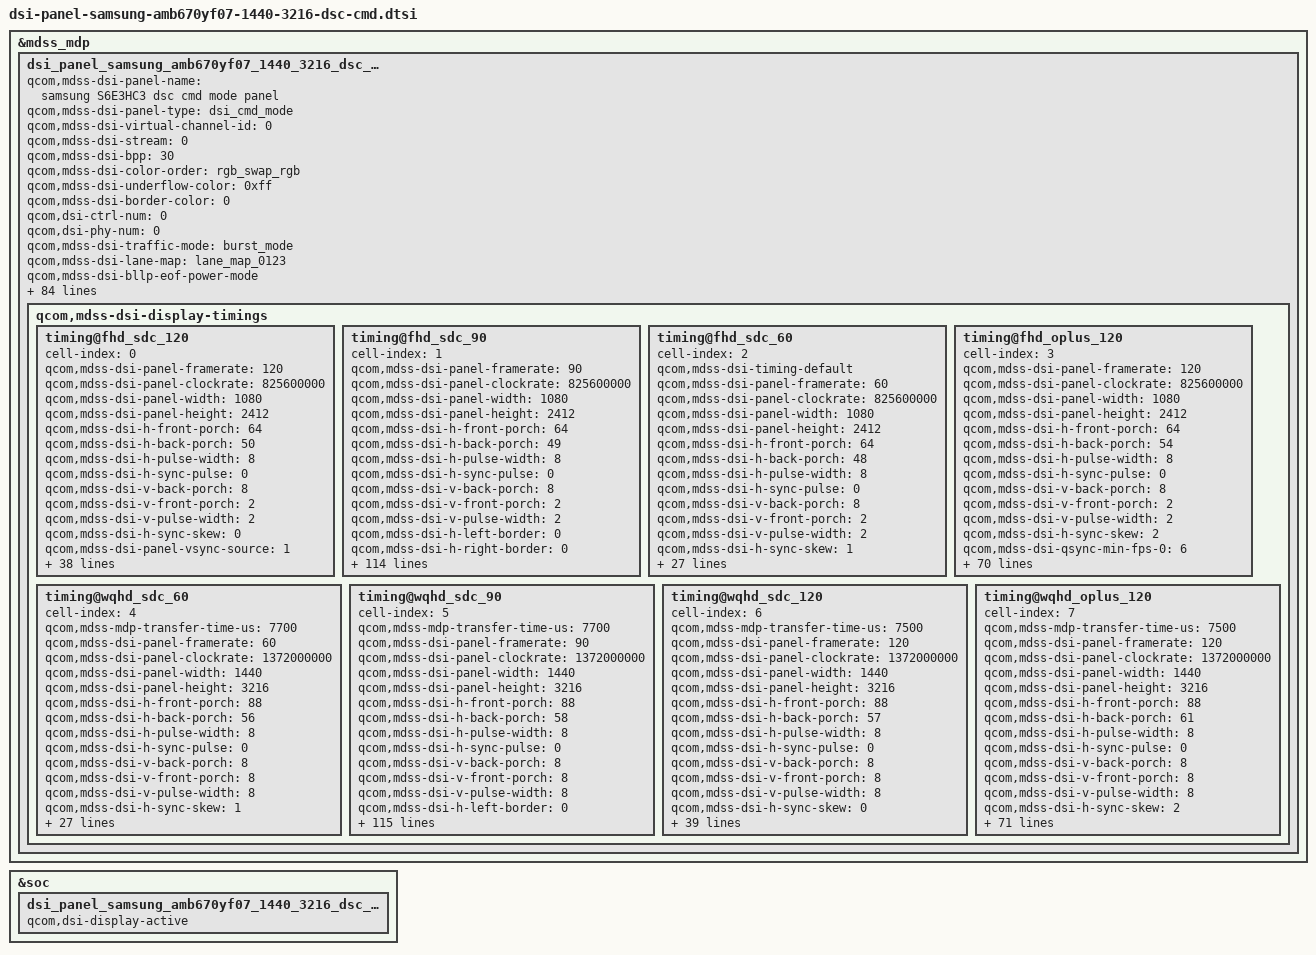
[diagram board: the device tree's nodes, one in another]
&mdss_mdp {
	dsi_panel_samsung_amb670yf07_1440_3216_dsc_cmd: qcom,mdss_dsi_panel_samsung_amb670yf07_1440_3216_dsc_cmd {
		qcom,mdss-dsi-panel-name = "samsung S6E3HC3 dsc cmd mode panel";
		qcom,mdss-dsi-panel-type = "dsi_cmd_mode";
		qcom,mdss-dsi-virtual-channel-id = <0>;
		qcom,mdss-dsi-stream = <0>;
		qcom,mdss-dsi-bpp = <30>;
		qcom,mdss-dsi-color-order = "rgb_swap_rgb";
		qcom,mdss-dsi-underflow-color = <0xff>;
		qcom,mdss-dsi-border-color = <0>;
		qcom,dsi-ctrl-num = <0>;
		qcom,dsi-phy-num = <0>;
		qcom,mdss-dsi-traffic-mode = "burst_mode";
		qcom,mdss-dsi-lane-map = "lane_map_0123";
		qcom,mdss-dsi-bllp-eof-power-mode;
		qcom,mdss-dsi-bllp-power-mode;
		qcom,mdss-dsi-lane-0-state;
		qcom,mdss-dsi-lane-1-state;
		qcom,mdss-dsi-lane-2-state;
		qcom,mdss-dsi-lane-3-state;
		qcom,mdss-dsi-dma-trigger = "trigger_sw";
		qcom,mdss-dsi-mdp-trigger = "none";
		qcom,mdss-dsi-reset-sequence = <1 10>, <0 5>, <1 10>;
		qcom,mdss-pan-physical-width-dimension = <70>;
		qcom,mdss-pan-physical-height-dimension = <156>;
		qcom,mdss-dsi-te-check-enable;
		qcom,mdss-dsi-te-using-te-pin;
		qcom,mdss-dsi-te-pin-select = <1>;
		qcom,mdss-dsi-te-dcs-command = <1>;
		qcom,mdss-dsi-wr-mem-start = <0x2c>;
		qcom,mdss-dsi-wr-mem-continue = <0x3c>;
		//qcom,mdss-dsi-lp11-init;
		qcom,mdss-dsi-init-delay-us = <1000>;
		qcom,mdss-dsi-panel-jitter = <0x4 0x1>;
		qcom,dynamic-mode-switch-enabled;
		qcom,dynamic-mode-switch-type = "dynamic-resolution-switch-immediate";
		/* HDR Setting */
		qcom,mdss-dsi-panel-hdr-enabled;
		qcom,mdss-dsi-panel-hdr-color-primaries = <15635 16450 34000 16000 13250 34500 7500 3000>;
		qcom,mdss-dsi-panel-peak-brightness = <5400000>;
		qcom,mdss-dsi-panel-average-brightness = <2000000>;
		qcom,mdss-dsi-panel-blackness-level = <2000>;

		qcom,esd-check-enabled;
		qcom,mdss-dsi-panel-status-check-mode = "reg_read";
		qcom,mdss-dsi-panel-status-command = [06 01 00 01 00 00 01 0A];
		qcom,mdss-dsi-panel-status-command-state = "dsi_lp_mode";
		qcom,mdss-dsi-panel-status-value = <
			0x9D
			0x9F
		>;
		qcom,mdss-dsi-panel-status-read-length = <1>;
		oplus,mdss-dsi-panel-status-match-modes = <0x00000000>;
		//oplus,esd-debug-enabled;

		qcom,mdss-dsi-display-timings {
			timing@fhd_sdc_120 {
				#include "dsi-panel-samsung-amb670yf07-1440-3216-dsc-cmd-common.dtsi"
				//qcom,mdss-mdp-transfer-time-us = <6000>;
				cell-index = <0>;
				qcom,mdss-dsi-panel-framerate = <120>;
				qcom,mdss-dsi-panel-clockrate = <825600000>;
				qcom,mdss-dsi-panel-width = <1080>;
				qcom,mdss-dsi-panel-height = <2412>;
				qcom,mdss-dsi-h-front-porch = <64>;
				qcom,mdss-dsi-h-back-porch = <50>;
				qcom,mdss-dsi-h-pulse-width = <8>;
				qcom,mdss-dsi-h-sync-pulse = <0>;
				qcom,mdss-dsi-v-back-porch = <8>;
				qcom,mdss-dsi-v-front-porch = <2>;
				qcom,mdss-dsi-v-pulse-width = <2>;

				/* SDC ADFR */
				qcom,mdss-dsi-h-sync-skew = <0>;
				qcom,mdss-dsi-panel-vsync-source = <1>;
				oplus,adfr-fakeframe-config = <3>;
				oplus,adfr-fakeframe-deferred-time = <6>;		/* period*0.7 */
				qcom,mdss-dsi-qsync-min-fps-0 = <1314>;
				qcom,mdss-dsi-qsync-min-fps-1 = <1314>;
				qcom,mdss-dsi-fakeframe-command = [
					05 00 00 40 00 00 01 2C
					05 00 00 40 00 00 01 3C
					05 00 00 40 00 00 01 2C
					05 00 00 40 00 00 01 3C
					05 00 00 00 00 00 01 00
				];

				qcom,mdss-dsi-timing-switch-command = [
					/* CASET/PASET Setting */
					39 00 00 40 00 00 05 2A 00 00 04 37
					39 00 00 40 00 00 05 2B 00 00 09 6B
					/* Scaler Setting */
					39 00 00 40 00 00 03 F0 5A 5A
					15 00 00 40 00 00 02 C3 89
					39 00 00 40 00 00 04 B0 00 24 C3
					39 00 00 40 00 00 12 C3 FD 00 FD 00 FD 00 FD 00 FD 00 FD 00 FD 00 FD 00 FD
					39 00 00 40 00 00 04 B0 00 3A C3
					39 00 00 40 00 00 12 C3 B0 00 B0 00 B0 00 B0 00 B0 00 B0 00 B0 00 B0 00 B0
					39 00 00 40 00 00 04 B0 00 50 C3
					39 00 00 40 00 00 12 C3 43 00 43 00 43 00 43 00 43 00 43 00 43 00 43 00 43
					39 00 00 40 00 00 04 B0 00 61 C3
					39 00 00 40 00 00 17 C3 CC CC CC CC C0 FE 00 FE 00 FE 00 FE 00 FE 00 FE 00 FE 00 FE 00 FE
					39 00 00 40 00 00 03 F0 A5 A5
					/* OPLUS ADFR OFF */
					39 00 00 40 00 00 03 F0 5A 5A
					39 00 00 40 00 00 03 FC 5A 5A
					15 00 00 40 00 00 02 B9 00						/* TP shift fixed */
					39 00 00 40 00 00 04 B0 00 02 60
					15 00 00 40 00 00 02 60 00						/* OPLUS ADFR OFF */
					39 00 00 40 00 00 03 F2 00 01					/* 0x01,0x00:ADFR ON setting 0x00,0x01:ADFR OFF Setting */
					15 00 00 40 00 00 02 F7 0F
					39 00 00 40 00 00 03 FC A5 A5
					39 00 00 40 00 00 03 F0 A5 A5

					/* TSP_SYNC1 Fixed Setting */
					39 00 00 40 00 00 03 F0 5A 5A
					39 00 00 40 00 00 04 B0 00 22 B9
					39 00 00 40 00 00 03 B9 A1 B1
					39 00 00 40 00 00 04 B0 00 3A B9
					15 00 00 40 00 00 02 B9 02						/* TSP_VSYNC Fixed TE 02:120 03:90 05:60 */
					39 00 00 40 00 00 04 B0 00 26 B9
					39 00 00 40 00 00 03 B9 00 00
					15 00 00 40 00 00 02 F7 0F
					39 00 00 40 00 00 03 F0 A5 A5
					/* TSP_SYNC3 Fixed Setting */
					39 00 00 40 00 00 03 F0 5A 5A
					39 00 00 40 00 00 04 B0 00 24 B9
					15 00 00 40 00 00 02 B9 21
					39 00 00 40 00 00 04 B0 00 38 B9
					15 00 00 40 00 00 02 B9 02						/* TSP_VSYNC Fixed TE 02:120 03:90 05:60 */
					39 00 00 40 00 00 04 B0 00 2A B9
					39 00 00 40 00 00 03 B9 00 00
					15 00 00 40 00 00 02 F7 0F
					39 00 00 40 00 00 03 F0 A5 A5

					/* 120hz Transition */
					39 00 00 40 00 00 03 F0 5A 5A
					39 00 00 40 00 00 04 B0 00 16 F2
					39 00 00 40 00 00 03 F2 1B 50
					39 00 00 40 00 00 04 B0 00 08 CB				/* power saving */
					15 00 00 40 00 00 02 CB 24
					15 00 00 40 00 00 02 60 00
					39 00 00 40 00 00 03 BD 23 02
					39 00 00 40 00 00 04 B0 00 10 BD
					15 00 00 40 00 00 02 BD 00
					39 00 00 40 00 00 04 B0 00 16 BD
					15 00 00 40 00 00 02 BD 77
					39 00 00 40 00 00 04 B0 00 14 BD
					15 00 00 40 00 00 02 BD 00
					15 00 00 40 00 00 02 F7 0F
					39 00 00 00 00 00 03 F0 A5 A5
				];
				qcom,mdss-dsi-on-command = [
					/* DSC Setting */
					39 00 00 00 00 00 5A 9E 12
					00 00 AB 30 80 09 6C 04 38
					00 24 02 1C 02 1C 02 00 02
					3B 00 20 03 35 00 07 00 0E
					03 34 02 D4 18 00 10 F0 07
					10 20 00 06 0F 0F 33 0E 1C
					2A 38 46 54 62 69 70 77 79
					7B 7D 7E 02 02 22 00 2A 40
					2A BE 3A FC 3A FA 3A F8 3B
					38 3B 78 3B B6 4B B6 4B F4
					4B F4 6C 34 84 74 00
					15 00 00 00 00 00 02 9D 01

					/* Sleep Out(11h) */
					05 00 00 00 06 00 01 11

					/* TSP_SYNC1 Fixed Setting */
					39 00 00 40 00 00 03 F0 5A 5A
					39 00 00 40 00 00 04 B0 00 22 B9
					39 00 00 40 00 00 03 B9 A1 B1
					39 00 00 40 00 00 04 B0 00 3A B9
					15 00 00 40 00 00 02 B9 02						/* TSP_VSYNC Fixed TE 02:120 03:90 05:60 */
					39 00 00 40 00 00 04 B0 00 26 B9
					39 00 00 40 00 00 03 B9 00 00
					15 00 00 40 00 00 02 F7 0F
					39 00 00 00 00 00 03 F0 A5 A5
					/* TSP_SYNC3 Fixed Setting */
					39 00 00 40 00 00 03 F0 5A 5A
					39 00 00 40 00 00 04 B0 00 24 B9
					15 00 00 40 00 00 02 B9 21
					39 00 00 40 00 00 04 B0 00 38 B9
					15 00 00 40 00 00 02 B9 02						/* TSP_VSYNC Fixed TE 02:120 03:90 05:60 */
					39 00 00 40 00 00 04 B0 00 2A B9
					39 00 00 40 00 00 03 B9 00 00
					15 00 00 40 00 00 02 F7 0F
					39 00 00 00 79 00 03 F0 A5 A5

					/* 120hz Transition */
					39 00 00 40 00 00 03 F0 5A 5A
					39 00 00 40 00 00 04 B0 00 16 F2
					39 00 00 40 00 00 03 F2 1B 50
					39 00 00 40 00 00 04 B0 00 08 CB				/* power saving */
					15 00 00 40 00 00 02 CB 24
					15 00 00 40 00 00 02 60 00
					39 00 00 40 00 00 03 BD 23 02
					39 00 00 40 00 00 04 B0 00 10 BD
					15 00 00 40 00 00 02 BD 00
					39 00 00 40 00 00 04 B0 00 16 BD
					15 00 00 40 00 00 02 BD 77
					39 00 00 40 00 00 04 B0 00 14 BD
					15 00 00 40 00 00 02 BD 00
					15 00 00 40 00 00 02 F7 0F
					39 00 00 00 00 00 03 F0 A5 A5

					/* Common Setting */
					39 00 00 40 00 00 03 F0 5A 5A
					39 00 00 40 00 00 03 F2 00 01					/* FQ_CON Setting */
					39 00 00 00 00 00 03 F0 A5 A5
					/* TE(Vsync) ON */
					39 00 00 40 00 00 03 F0 5A 5A
					15 00 00 40 00 00 02 35 00
					15 00 00 40 00 00 02 B9 00
					39 00 00 00 00 00 03 F0 A5 A5
					/* CASET/PASET Setting */
					39 00 00 00 00 00 05 2A 00 00 04 37
					39 00 00 00 00 00 05 2B 00 00 09 6B
					/* Scaler Setting */
					39 00 00 40 00 00 03 F0 5A 5A
					15 00 00 40 00 00 02 C3 89
					39 00 00 40 00 00 04 B0 00 24 C3
					39 00 00 40 00 00 12 C3 FD 00 FD 00 FD 00 FD 00 FD 00 FD 00 FD 00 FD 00 FD
					39 00 00 40 00 00 04 B0 00 3A C3
					39 00 00 40 00 00 12 C3 B0 00 B0 00 B0 00 B0 00 B0 00 B0 00 B0 00 B0 00 B0
					39 00 00 40 00 00 04 B0 00 50 C3
					39 00 00 40 00 00 12 C3 43 00 43 00 43 00 43 00 43 00 43 00 43 00 43 00 43
					39 00 00 40 00 00 04 B0 00 61 C3
					39 00 00 40 00 00 17 C3 CC CC CC CC C0 FE 00 FE 00 FE 00 FE 00 FE 00 FE 00 FE 00 FE 00 FE
					39 00 00 00 00 00 03 F0 A5 A5
					/* Pre-charge time setting */
					39 00 00 40 00 00 03 F0 5A 5A
					39 00 00 40 00 00 04 B0 00 2B F6
					39 00 00 40 00 00 04 F6 60 63 69
					15 00 00 40 00 00 02 F7 0F
					39 00 00 00 00 00 03 F0 A5 A5
					/* HLPM Power Saving */
					39 00 00 40 00 00 03 F0 5A 5A
					39 00 00 40 00 00 04 B0 00 46 F4
					15 00 00 40 00 00 02 F4 08
					39 00 00 00 00 00 03 F0 A5 A5
					/* DCDC setting of AOD Sequence */
					39 00 00 40 00 00 03 F0 5A 5A
					39 00 00 40 00 00 04 B0 00 18 B1
					39 00 00 40 00 00 02 B1 05
					39 00 00 00 00 00 03 F0 A5 A5

					/* Brightness Control */
					39 00 00 40 00 00 03 F0 5A 5A
					39 00 00 40 00 00 04 B0 00 0D 63
					15 00 00 40 00 00 02 63 01						/* Dimming Setting */
					39 00 00 40 00 00 04 B0 00 0C 63
					15 00 00 40 00 00 02 63 20
					39 00 00 00 00 00 03 F0 A5 A5
					15 00 00 00 00 00 02 53 28
					15 00 00 00 00 00 02 F7 0F
					/* ACL Mode */
					39 00 00 40 00 00 03 F0 5A 5A
					15 00 00 40 00 00 02 55 00
					39 00 00 00 00 00 03 F0 A5 A5
					/* OPEC Setting */
					39 00 00 40 00 00 03 F0 5A 5A
					39 00 00 40 00 00 04 B0 00 52 1F
					15 00 00 40 00 00 02 1F 02
					39 00 00 40 00 00 04 B0 00 54 1F
					15 00 00 40 00 00 02 1F 00
					39 00 00 00 00 00 03 F0 A5 A5
				];

				qcom,mdss-dsi-qsync-on-commands = [
					/* SDC Auto On */
					39 00 00 40 00 00 03 F0 5A 5A
					15 00 00 40 00 00 02 BD 23
					39 00 00 40 00 00 04 B0 00 10 BD
					15 00 00 40 00 00 02 BD 10
					39 00 00 40 00 00 04 B0 00 16 BD
					15 00 00 40 00 00 02 BD 03
					15 00 00 40 00 00 02 F7 0F
					39 00 00 00 00 00 03 F0 A5 A5
				];
				qcom,mdss-dsi-qsync-off-commands = [
					/* SDC Auto Off */
					39 00 00 40 00 00 03 F0 5A 5A
					15 00 00 40 00 00 02 BD 23
					39 00 00 40 00 00 04 B0 00 10 BD
					15 00 00 40 00 00 02 BD 00
					39 00 00 40 00 00 04 B0 00 16 BD
					15 00 00 40 00 00 02 BD 77
					15 00 00 40 00 00 02 F7 0F
					39 00 00 00 00 00 03 F0 A5 A5
				];
				qcom,mdss-dsi-qsync-min-fps-0-command = [
					/* SDC Auto Off */
					39 00 00 40 00 00 03 F0 5A 5A
					39 00 00 40 00 00 04 B0 00 14 BD
					15 00 00 40 00 00 02 BD 00
					15 00 00 40 00 00 02 F7 0F
					39 00 00 00 00 00 03 F0 A5 A5
				];
				qcom,mdss-dsi-qsync-min-fps-1-command = [
					/* SDC Auto On */
					39 00 00 40 00 00 03 F0 5A 5A
					39 00 00 40 00 00 04 B0 00 14 BD
					15 00 00 40 00 00 02 BD 00
					15 00 00 40 00 00 02 F7 0F
					39 00 00 00 00 00 03 F0 A5 A5
				];

				qcom,mdss-dsi-fakeframe-command-state = "dsi_hs_mode";
				qcom,mdss-dsi-qsync-on-commands-state ="dsi_hs_mode";
				qcom,mdss-dsi-qsync-off-commands-state ="dsi_hs_mode";
				qcom,mdss-dsi-qsync-min-fps-0-command-state = "dsi_hs_mode";
				qcom,mdss-dsi-qsync-min-fps-1-command-state = "dsi_hs_mode";
				qcom,panel-roi-alignment=<1080 36 1080 36 1080 36>;
				qcom,partial-update-enabled = "single_roi";

				qcom,lm-split = <540 540>;
				qcom,mdss-dsc-slice-height = <36>;
				qcom,mdss-dsc-slice-width = <540>;
			};

			timing@fhd_sdc_90 {
				//qcom,mdss-mdp-transfer-time-us = <6000>;
				cell-index = <1>;
				qcom,mdss-dsi-panel-framerate = <90>;
				qcom,mdss-dsi-panel-clockrate = <825600000>;
				qcom,mdss-dsi-panel-width = <1080>;
				qcom,mdss-dsi-panel-height = <2412>;
				qcom,mdss-dsi-h-front-porch = <64>;
				qcom,mdss-dsi-h-back-porch = <49>;
				qcom,mdss-dsi-h-pulse-width = <8>;
				qcom,mdss-dsi-h-sync-pulse = <0>;
				qcom,mdss-dsi-v-back-porch = <8>;
				qcom,mdss-dsi-v-front-porch = <2>;
				qcom,mdss-dsi-v-pulse-width = <2>;
				qcom,mdss-dsi-h-left-border = <0>;
				qcom,mdss-dsi-h-right-border = <0>;
				qcom,mdss-dsi-v-top-border = <0>;
				qcom,mdss-dsi-v-bottom-border = <0>;
				qcom,mdss-dsi-panel-jitter = <0x4 0x1>;

				/* ofp config */
				oplus,ofp-need-to-separate-backlight;
				oplus,ofp-hbm-on-period = <2>;

				/* SDC ADFR */
				qcom,mdss-dsi-h-sync-skew = <0>;
				qcom,mdss-dsi-panel-vsync-source = <1>;
				oplus,adfr-fakeframe-config = <3>;
				oplus,adfr-fakeframe-deferred-time = <8>;		/* period*0.7 */
				qcom,mdss-dsi-qsync-min-fps-0 = <1314>;
				qcom,mdss-dsi-qsync-min-fps-1 = <1314>;
				qcom,mdss-dsi-fakeframe-command = [
					05 00 00 40 00 00 01 2C
					05 00 00 40 00 00 01 3C
					05 00 00 40 00 00 01 2C
					05 00 00 40 00 00 01 3C
					05 00 00 00 00 00 01 00
				];
				qcom,mdss-dsi-adfr-pre-switch-command = [
					39 00 00 40 00 00 03 F0 5A 5A					/* Level2 key Access Enable */
					39 00 00 40 00 00 04 B0 00 14 BD
					15 00 00 40 00 00 02 BD 00						/* SDC auto mode min == max */
					15 00 00 40 00 00 02 BD 23						/* 21 : Manual On  23 Auto On */
					15 00 00 40 00 00 02 F7 0F
					39 00 00 00 00 00 03 F0 A5 A5					/* Level2 key Access Disable */
				];

				qcom,mdss-dsi-timing-switch-command = [
					/* CASET/PASET Setting */
					39 00 00 40 00 00 05 2A 00 00 04 37
					39 00 00 40 00 00 05 2B 00 00 09 6B
					/* Scaler Setting */
					39 00 00 40 00 00 03 F0 5A 5A
					15 00 00 40 00 00 02 C3 89
					39 00 00 40 00 00 04 B0 00 24 C3
					39 00 00 40 00 00 12 C3 FD 00 FD 00 FD 00 FD 00 FD 00 FD 00 FD 00 FD 00 FD
					39 00 00 40 00 00 04 B0 00 3A C3
					39 00 00 40 00 00 12 C3 B0 00 B0 00 B0 00 B0 00 B0 00 B0 00 B0 00 B0 00 B0
					39 00 00 40 00 00 04 B0 00 50 C3
					39 00 00 40 00 00 12 C3 43 00 43 00 43 00 43 00 43 00 43 00 43 00 43 00 43
					39 00 00 40 00 00 04 B0 00 61 C3
					39 00 00 40 00 00 17 C3 CC CC CC CC C0 FE 00 FE 00 FE 00 FE 00 FE 00 FE 00 FE 00 FE 00 FE
					39 00 00 40 00 00 03 F0 A5 A5
					/* OPLUS ADFR OFF */
					39 00 00 40 00 00 03 F0 5A 5A
					39 00 00 40 00 00 03 FC 5A 5A
					15 00 00 40 00 00 02 B9 00						/* TP shift fixed */
					39 00 00 40 00 00 04 B0 00 02 60
					15 00 00 40 00 00 02 60 00						/* OPLUS ADFR OFF */
					39 00 00 40 00 00 03 F2 00 01					/* 0x01,0x00:ADFR ON setting 0x00,0x01:ADFR OFF Setting */
					15 00 00 40 00 00 02 F7 0F
					39 00 00 40 00 00 03 FC A5 A5
					39 00 00 40 00 00 03 F0 A5 A5

					/* TSP_SYNC1 Fixed Setting */
					39 00 00 40 00 00 03 F0 5A 5A
					39 00 00 40 00 00 04 B0 00 22 B9
					39 00 00 40 00 00 03 B9 A1 B1
					39 00 00 40 00 00 04 B0 00 3A B9
					15 00 00 40 00 00 02 B9 03						/* TSP_VSYNC Fixed TE 02:120 03:90 05:60 */
					39 00 00 40 00 00 04 B0 00 26 B9
					39 00 00 40 00 00 03 B9 00 00
					15 00 00 40 00 00 02 F7 0F
					39 00 00 40 00 00 03 F0 A5 A5
					/* TSP_SYNC3 Fixed Setting */
					39 00 00 40 00 00 03 F0 5A 5A
					39 00 00 40 00 00 04 B0 00 24 B9
					15 00 00 40 00 00 02 B9 21
					39 00 00 40 00 00 04 B0 00 38 B9
					15 00 00 40 00 00 02 B9 03						/* TSP_VSYNC Fixed TE 02:120 03:90 05:60 */
					39 00 00 40 00 00 04 B0 00 2A B9
					39 00 00 40 00 00 03 B9 00 00
					15 00 00 40 00 00 02 F7 0F
					39 00 00 40 00 00 03 F0 A5 A5

					/* 90hz Transition */
					39 00 00 40 00 00 03 F0 5A 5A
					39 00 00 40 00 00 04 B0 00 16 F2
					39 00 00 40 00 00 03 F2 1B 50
					39 00 00 40 00 00 04 B0 00 08 CB				/* power saving */
					15 00 00 40 00 00 02 CB A4
					39 00 00 40 00 00 03 BD 21 82
					15 00 00 40 00 00 02 60 09
					39 00 00 40 00 00 04 B0 00 10 BD
					15 00 00 40 00 00 02 BD 00
					15 00 00 40 00 00 02 F7 0F
					39 00 00 00 00 00 03 F0 A5 A5
				];
				qcom,mdss-dsi-on-command = [
					/* DSC Setting */
					39 00 00 00 00 00 5A 9E 12
					00 00 AB 30 80 09 6C 04 38
					00 24 02 1C 02 1C 02 00 02
					3B 00 20 03 35 00 07 00 0E
					03 34 02 D4 18 00 10 F0 07
					10 20 00 06 0F 0F 33 0E 1C
					2A 38 46 54 62 69 70 77 79
					7B 7D 7E 02 02 22 00 2A 40
					2A BE 3A FC 3A FA 3A F8 3B
					38 3B 78 3B B6 4B B6 4B F4
					4B F4 6C 34 84 74 00
					15 00 00 00 00 00 02 9D 01

					/* Sleep Out(11h) */
					05 00 00 00 06 00 01 11

					/* TSP_SYNC1 Fixed Setting */
					39 00 00 40 00 00 03 F0 5A 5A
					39 00 00 40 00 00 04 B0 00 22 B9
					39 00 00 40 00 00 03 B9 A1 B1
					39 00 00 40 00 00 04 B0 00 3A B9
					15 00 00 40 00 00 02 B9 03						/* TSP_VSYNC Fixed TE 02:120 03:90 05:60 */
					39 00 00 40 00 00 04 B0 00 26 B9
					39 00 00 40 00 00 03 B9 00 00
					15 00 00 40 00 00 02 F7 0F
					39 00 00 00 00 00 03 F0 A5 A5
					/* TSP_SYNC3 Fixed Setting */
					39 00 00 40 00 00 03 F0 5A 5A
					39 00 00 40 00 00 04 B0 00 24 B9
					15 00 00 40 00 00 02 B9 21
					39 00 00 40 00 00 04 B0 00 38 B9
					15 00 00 40 00 00 02 B9 03						/* TSP_VSYNC Fixed TE 02:120 03:90 05:60 */
					39 00 00 40 00 00 04 B0 00 2A B9
					39 00 00 40 00 00 03 B9 00 00
					15 00 00 40 00 00 02 F7 0F
					39 00 00 00 79 00 03 F0 A5 A5

					/* 90hz Transition */
					39 00 00 40 00 00 03 F0 5A 5A
					39 00 00 40 00 00 04 B0 00 16 F2
					39 00 00 40 00 00 03 F2 1B 50
					39 00 00 40 00 00 04 B0 00 08 CB				/* power saving */
					15 00 00 40 00 00 02 CB A4
					39 00 00 40 00 00 03 BD 21 82
					15 00 00 40 00 00 02 60 09
					39 00 00 40 00 00 04 B0 00 10 BD
					15 00 00 40 00 00 02 BD 00
					15 00 00 40 00 00 02 F7 0F
					39 00 00 00 00 00 03 F0 A5 A5

					/* Common Setting */
					39 00 00 40 00 00 03 F0 5A 5A
					39 00 00 40 00 00 03 F2 00 01					/* FQ_CON Setting */
					39 00 00 00 00 00 03 F0 A5 A5
					/* TE(Vsync) ON */
					39 00 00 40 00 00 03 F0 5A 5A
					15 00 00 40 00 00 02 35 00
					15 00 00 40 00 00 02 B9 00
					39 00 00 00 00 00 03 F0 A5 A5
					/* CASET/PASET Setting */
					39 00 00 00 00 00 05 2A 00 00 04 37
					39 00 00 00 00 00 05 2B 00 00 09 6B
					/* Scaler Setting */
					39 00 00 40 00 00 03 F0 5A 5A
					15 00 00 40 00 00 02 C3 89
					39 00 00 40 00 00 04 B0 00 24 C3
					39 00 00 40 00 00 12 C3 FD 00 FD 00 FD 00 FD 00 FD 00 FD 00 FD 00 FD 00 FD
					39 00 00 40 00 00 04 B0 00 3A C3
					39 00 00 40 00 00 12 C3 B0 00 B0 00 B0 00 B0 00 B0 00 B0 00 B0 00 B0 00 B0
					39 00 00 40 00 00 04 B0 00 50 C3
					39 00 00 40 00 00 12 C3 43 00 43 00 43 00 43 00 43 00 43 00 43 00 43 00 43
					39 00 00 40 00 00 04 B0 00 61 C3
					39 00 00 40 00 00 17 C3 CC CC CC CC C0 FE 00 FE 00 FE 00 FE 00 FE 00 FE 00 FE 00 FE 00 FE
					39 00 00 00 00 00 03 F0 A5 A5
					/* Pre-charge time setting */
					39 00 00 40 00 00 03 F0 5A 5A
					39 00 00 40 00 00 04 B0 00 2B F6
					39 00 00 40 00 00 04 F6 60 63 69
					15 00 00 40 00 00 02 F7 0F
					39 00 00 00 00 00 03 F0 A5 A5
					/* HLPM Power Saving */
					39 00 00 40 00 00 03 F0 5A 5A
					39 00 00 40 00 00 04 B0 00 46 F4
					15 00 00 40 00 00 02 F4 08
					39 00 00 00 00 00 03 F0 A5 A5
					/* DCDC setting of AOD Sequence */
					39 00 00 40 00 00 03 F0 5A 5A
					39 00 00 40 00 00 04 B0 00 18 B1
					39 00 00 40 00 00 02 B1 05
					39 00 00 00 00 00 03 F0 A5 A5

					/* Brightness Control */
					39 00 00 40 00 00 03 F0 5A 5A
					39 00 00 40 00 00 04 B0 00 0D 63
					15 00 00 40 00 00 02 63 01						/* Dimming Setting */
					39 00 00 40 00 00 04 B0 00 0C 63
					15 00 00 40 00 00 02 63 20
					39 00 00 00 00 00 03 F0 A5 A5
					15 00 00 00 00 00 02 53 28
					15 00 00 00 00 00 02 F7 0F
					/* ACL Mode */
					39 00 00 40 00 00 03 F0 5A 5A
					15 00 00 40 00 00 02 55 00
					39 00 00 00 00 00 03 F0 A5 A5
					/* OPEC Setting */
					39 00 00 40 00 00 03 F0 5A 5A
					39 00 00 40 00 00 04 B0 00 52 1F
					15 00 00 40 00 00 02 1F 02
					39 00 00 40 00 00 04 B0 00 54 1F
					15 00 00 40 00 00 02 1F 00
					39 00 00 00 00 00 03 F0 A5 A5
				];
				qcom,mdss-dsi-post-on-backlight = [
					/* Display On */
					05 00 00 00 00 00 01 29
				];
				qcom,mdss-dsi-off-command = [
					/* Display Off */
					05 00 00 00 15 00 02 28 00
					/* Sleep In */
					05 00 00 00 65 00 02 10 00
				];

				qcom,mdss-dsi-qsync-on-commands = [
				];
				qcom,mdss-dsi-qsync-off-commands = [
				];
				qcom,mdss-dsi-qsync-min-fps-0-command = [
				];
				qcom,mdss-dsi-qsync-min-fps-1-command = [
				];

				qcom,mdss-dsi-hbm-enter-switch-command = [
					/* HBM Mode ON */
					15 00 00 40 00 00 02 53 E0
					39 00 00 00 00 00 03 51 0D D2
				];
				qcom,mdss-dsi-hbm-exit-switch-command = [
					/* HBM Mode OFF */
					15 00 00 40 00 00 02 53 20
					39 00 00 00 00 00 03 51 07 FF
				];

				qcom,mdss-dsi-hbm-on-command = [
					39 00 00 40 00 00 03 F0 5A 5A
					39 00 00 00 0B 00 03 F0 A5 A5
					/* HBM Mode ON */
					15 00 00 40 00 00 02 53 E0
					39 00 00 00 0B 00 03 51 0E FF
					/* AID Cycle + AOR Change Setting */
					39 00 00 40 00 00 03 F0 5A 5A
					39 00 00 40 00 00 04 B0 00 01 BD
					15 00 00 40 00 00 02 BD 02
					39 00 00 40 00 00 04 B0 02 B9 65
					39 00 00 40 00 00 07 65 00 AC 00 AC 00 AC
					15 00 00 40 00 00 02 F7 0F
					39 00 00 00 00 00 03 F0 A5 A5
				];
				qcom,mdss-dsi-hbm-off-command = [
					/* HBM Mode OFF */
					15 00 00 40 00 00 02 53 28
					39 00 00 00 0B 00 03 51 06 9F
					/* AID Cycle + AOR Change Setting */
					39 00 00 40 00 00 03 F0 5A 5A
					39 00 00 40 00 00 04 B0 00 01 BD
					15 00 00 40 00 00 02 BD 02
					39 00 00 40 00 00 04 B0 02 B9 65
					39 00 00 40 00 00 07 65 01 5E 01 5E 01 5E
					15 00 00 40 00 00 02 F7 0F
					39 00 00 00 00 00 03 F0 A5 A5
				];
				qcom,mdss-dsi-lp1-command = [
					05 00 00 00 0C 00 01 28
					/* AOD Mode ON */
					39 00 00 40 00 00 03 F0 5A 5A
					15 00 00 40 00 00 02 53 24
					39 00 00 00 00 00 03 F0 A5 A5
				];
				qcom,mdss-dsi-nolp-command = [
					05 00 00 00 0C 00 01 28
					/* AOD Mode OFF */
					39 00 00 40 00 00 03 F0 5A 5A
					15 00 00 40 00 00 02 53 28
					39 00 00 40 00 00 03 51 00 00
					39 00 00 00 0C 00 03 F0 A5 A5
					05 00 00 00 00 00 01 29
				];
				qcom,mdss-dsi-aod-high-mode-command = [
					/* AOD High Mode, 50nit */
					39 00 00 40 00 00 03 F0 5A 5A
					15 00 00 40 00 00 02 53 24
					39 00 00 00 00 00 03 F0 A5 A5
				];
				qcom,mdss-dsi-aod-low-mode-command = [
					/* AOD Low Mode 10nit */
					39 00 00 40 00 00 03 F0 5A 5A
					15 00 00 40 00 00 02 53 27
					39 00 00 40 00 00 04 B0 03 55 65
					39 00 00 40 00 00 03 65 14 40
					39 00 00 00 00 00 03 F0 A5 A5
				];
				qcom,mdss-dsi-ultra-low-power-aod-on-command = [
					39 00 00 40 00 00 03 F0 5A 5A
					39 00 00 40 00 00 04 B0 00 01 60
					15 00 00 40 00 00 02 60 05
					15 00 00 40 00 00 02 F7 0F
					39 00 00 00 00 00 03 F0 A5 A5
				];
				qcom,mdss-dsi-ultra-low-power-aod-off-command = [
					39 00 00 40 00 00 03 F0 5A 5A
					39 00 00 40 00 00 04 B0 00 01 60
					15 00 00 40 00 00 02 60 00
					15 00 00 40 00 00 02 F7 0F
					39 00 00 00 24 00 03 F0 A5 A5
				];

				qcom,mdss-dsi-loading-effect-1-command = [
					39 00 00 40 00 00 03 F0 5A 5A
					39 00 00 40 00 00 04 B0 02 B6 1D
					15 00 00 40 00 00 02 1D 27
					39 00 00 40 00 00 04 B0 02 B7 1D
					39 00 00 40 00 00 04 1D F9 03 6C
					39 00 00 40 00 00 04 B0 02 C2 1D
					39 00 00 40 00 00 0A 1D 43 4C 82 0A 0B 09 27 2A 24
					39 00 00 40 00 00 04 B0 02 CC 1D
					39 00 00 40 00 00 09 1D 38 30 3E 43 39 41 46 3C
					39 00 00 40 00 00 04 B0 01 A5 1F
					39 00 00 40 00 00 09 1F E2 00 00 00 92 2C 6A 80
					39 00 00 40 00 00 04 B0 01 AD 1F
					39 00 00 40 00 00 07 1F 00 00 00 00 FF 90
					39 00 00 40 00 00 04 B0 01 B5 1F
					39 00 00 40 00 00 04 1F 49 00 10
					39 00 00 40 00 00 04 B0 01 BA 1F
					39 00 00 40 00 00 06 1F 05 FF 10 00 00
					39 00 00 40 00 00 04 B0 01 C1 1F
					39 00 00 40 00 00 05 1F 00 00 00 00
					39 00 00 40 00 00 04 B0 01 C5 1F
					39 00 00 40 00 00 05 1F 03 FF 21 3C
					39 00 00 00 00 00 03 F0 A5 A5
				];
				qcom,mdss-dsi-loading-effect-2-command = [
					39 00 00 40 00 00 03 F0 5A 5A
					39 00 00 40 00 00 04 B0 02 B6 1D
					15 00 00 40 00 00 02 1D 27
					39 00 00 40 00 00 04 B0 02 B7 1D
					39 00 00 40 00 00 04 1D F9 03 6C
					39 00 00 40 00 00 04 B0 02 C2 1D
					39 00 00 40 00 00 0A 1D 43 4C 82 0A 0B 09 27 2A 24
					39 00 00 40 00 00 04 B0 02 CC 1D
					39 00 00 40 00 00 09 1D 38 30 3E 43 39 41 46 3C
					39 00 00 40 00 00 04 B0 01 A5 1F
					39 00 00 40 00 00 09 1F E2 00 00 00 92 2C 6A 80
					39 00 00 40 00 00 04 B0 01 AD 1F
					39 00 00 40 00 00 07 1F 7D 64 7E 65 FF 90
					39 00 00 40 00 00 04 B0 01 B5 1F
					39 00 00 40 00 00 04 1F 49 00 10
					39 00 00 40 00 00 04 B0 01 BA 1F
					39 00 00 40 00 00 06 1F 05 FF 10 00 00
					39 00 00 40 00 00 04 B0 01 C1 1F
					39 00 00 40 00 00 05 1F 00 00 00 00
					39 00 00 40 00 00 04 B0 01 C5 1F
					39 00 00 40 00 00 05 1F 03 FF 21 3C
					39 00 00 00 00 00 03 F0 A5 A5
				];
				qcom,mdss-dsi-loading-effect-off-command = [
					39 00 00 40 00 00 03 F0 5A 5A
					39 00 00 40 00 00 04 B0 02 B6 1D
					15 00 00 40 00 00 02 1D 07
					39 00 00 40 00 00 04 B0 02 B7 1D
					39 00 00 40 00 00 04 1D F9 03 6C
					39 00 00 40 00 00 04 B0 02 C2 1D
					39 00 00 40 00 00 0A 1D 43 4C 82 0A 0B 09 27 2A 24
					39 00 00 40 00 00 04 B0 02 CC 1D
					39 00 00 40 00 00 09 1D 38 30 3E 43 39 41 46 3C
					39 00 00 40 00 00 04 B0 01 A5 1F
					39 00 00 40 00 00 09 1F E2 00 00 00 92 2C 6A 80
					39 00 00 40 00 00 04 B0 01 AD 1F
					39 00 00 40 00 00 07 1F 61 1A 64 1D FF 9F
					39 00 00 40 00 00 04 B0 01 B5 1F
					39 00 00 40 00 00 04 1F 49 00 10
					39 00 00 40 00 00 04 B0 01 BA 1F
					39 00 00 40 00 00 06 1F 05 FF 10 00 00
					39 00 00 40 00 00 04 B0 01 C1 1F
					39 00 00 40 00 00 05 1F 00 00 00 00
					39 00 00 40 00 00 04 B0 01 C5 1F
					39 00 00 40 00 00 05 1F 03 FF 21 3C
					39 00 00 00 00 00 03 F0 A5 A5
				];

				qcom,mdss-dsi-panel-read-register-open-command = [
					39 00 00 00 00 00 03 F0 5A 5A
				];
				qcom,mdss-dsi-panel-id1-command = [
					06 00 00 00 00 00 01 E9
				];
				qcom,mdss-dsi-panel-read-register-close-command = [
					39 00 00 00 00 00 03 F0 A5 A5
				];

				qcom,mdss-dsi-fakeframe-command-state = "dsi_hs_mode";
				qcom,mdss-dsi-adfr-pre-switch-command-state = "dsi_hs_mode";
				qcom,mdss-dsi-timing-switch-command-state = "dsi_hs_mode";
				qcom,mdss-dsi-qsync-on-commands-state ="dsi_hs_mode";
				qcom,mdss-dsi-qsync-off-commands-state ="dsi_hs_mode";
				qcom,mdss-dsi-qsync-min-fps-0-command-state = "dsi_hs_mode";
				qcom,mdss-dsi-qsync-min-fps-1-command-state = "dsi_hs_mode";
				qcom,mdss-dsi-hbm-enter-switch-command-state = "dsi_hs_mode";
				qcom,mdss-dsi-hbm-exit-switch-command-state = "dsi_hs_mode";
				qcom,mdss-dsi-hbm-on-command-state = "dsi_hs_mode";
				qcom,mdss-dsi-hbm-off-command-state = "dsi_hs_mode";
				qcom,mdss-dsi-lp1-command-state = "dsi_hs_mode";
				qcom,mdss-dsi-nolp-command-state = "dsi_hs_mode";
				qcom,mdss-dsi-aod-high-mode-command-state = "dsi_hs_mode";
				qcom,mdss-dsi-aod-low-mode-command-state = "dsi_hs_mode";
				qcom,mdss-dsi-ultra-low-power-aod-on-command-state = "dsi_hs_mode";
				qcom,mdss-dsi-ultra-low-power-aod-off-command-state = "dsi_hs_mode";
				qcom,mdss-dsi-loading-effect-1-command-state = "dsi_hs_mode";
				qcom,mdss-dsi-loading-effect-2-command-state = "dsi_hs_mode";
				qcom,mdss-dsi-loading-effect-off-command-state = "dsi_hs_mode";
				qcom,panel-roi-alignment=<1080 36 1080 36 1080 36>;
				qcom,partial-update-enabled = "single_roi";

				qcom,lm-split = <540 540>;
				qcom,compression-mode = "dsc";
				qcom,mdss-dsc-encoders = <2>;
				qcom,mdss-dsc-slice-height = <36>;
				qcom,mdss-dsc-slice-width = <540>;
				qcom,mdss-dsc-slice-per-pkt = <2>;
				qcom,mdss-dsc-bit-per-component = <10>;
				qcom,mdss-dsc-bit-per-pixel = <8>;
				qcom,mdss-dsc-version = <0x12>;
				//qcom,mdss-dsc-scr-version = <1>;
				qcom,mdss-dsc-block-prediction-enable;
			};

			timing@fhd_sdc_60 {
				#include "dsi-panel-samsung-amb670yf07-1440-3216-dsc-60fps-cmd-common.dtsi"
				//qcom,mdss-mdp-transfer-time-us = <6000>;
				cell-index = <2>;
				qcom,mdss-dsi-timing-default;
				qcom,mdss-dsi-panel-framerate = <60>;
				qcom,mdss-dsi-panel-clockrate = <825600000>;
				qcom,mdss-dsi-panel-width = <1080>;
				qcom,mdss-dsi-panel-height = <2412>;
				qcom,mdss-dsi-h-front-porch = <64>;
				qcom,mdss-dsi-h-back-porch = <48>;
				qcom,mdss-dsi-h-pulse-width = <8>;
				qcom,mdss-dsi-h-sync-pulse = <0>;
				qcom,mdss-dsi-v-back-porch = <8>;
				qcom,mdss-dsi-v-front-porch = <2>;
				qcom,mdss-dsi-v-pulse-width = <2>;

				/* SDC MFR */
				qcom,mdss-dsi-h-sync-skew = <1>;
				qcom,mdss-dsi-panel-vsync-source = <1>;
				qcom,mdss-dsi-qsync-min-fps-0 = <1314>;

				qcom,mdss-dsi-timing-switch-command = [
					/* CASET/PASET Setting */
					39 00 00 40 00 00 05 2A 00 00 04 37
					39 00 00 40 00 00 05 2B 00 00 09 6B
					/* Scaler Setting */
					39 00 00 40 00 00 03 F0 5A 5A
					15 00 00 40 00 00 02 C3 89
					39 00 00 40 00 00 04 B0 00 24 C3
					39 00 00 40 00 00 12 C3 FD 00 FD 00 FD 00 FD 00 FD 00 FD 00 FD 00 FD 00 FD
					39 00 00 40 00 00 04 B0 00 3A C3
					39 00 00 40 00 00 12 C3 B0 00 B0 00 B0 00 B0 00 B0 00 B0 00 B0 00 B0 00 B0
					39 00 00 40 00 00 04 B0 00 50 C3
					39 00 00 40 00 00 12 C3 43 00 43 00 43 00 43 00 43 00 43 00 43 00 43 00 43
					39 00 00 40 00 00 04 B0 00 61 C3
					39 00 00 40 00 00 17 C3 CC CC CC CC C0 FE 00 FE 00 FE 00 FE 00 FE 00 FE 00 FE 00 FE 00 FE
					39 00 00 40 00 00 03 F0 A5 A5
					/* OPLUS ADFR OFF */
					39 00 00 40 00 00 03 F0 5A 5A
					39 00 00 40 00 00 03 FC 5A 5A
					15 00 00 40 00 00 02 B9 00						/* TP shift fixed */
					39 00 00 40 00 00 04 B0 00 02 60
					15 00 00 40 00 00 02 60 00						/* OPLUS ADFR OFF */
					39 00 00 40 00 00 03 F2 00 01					/* 0x01,0x00:ADFR ON setting 0x00,0x01:ADFR OFF Setting */
					15 00 00 40 00 00 02 F7 0F
					39 00 00 40 00 00 03 FC A5 A5
					39 00 00 40 00 00 03 F0 A5 A5

					/* TSP_SYNC1 Fixed Setting */
					39 00 00 40 00 00 03 F0 5A 5A
					39 00 00 40 00 00 04 B0 00 22 B9
					39 00 00 40 00 00 03 B9 A1 B1
					39 00 00 40 00 00 04 B0 00 3A B9
					15 00 00 40 00 00 02 B9 05						/* TSP_VSYNC Fixed TE 02:120 03:90 05:60 */
					39 00 00 40 00 00 04 B0 00 26 B9
					39 00 00 40 00 00 03 B9 00 00
					15 00 00 40 00 00 02 F7 0F
					39 00 00 40 00 00 03 F0 A5 A5
					/* TSP_SYNC3 Fixed Setting */
					39 00 00 40 00 00 03 F0 5A 5A
					39 00 00 40 00 00 04 B0 00 24 B9
					15 00 00 40 00 00 02 B9 21
					39 00 00 40 00 00 04 B0 00 38 B9
					15 00 00 40 00 00 02 B9 05						/* TSP_VSYNC Fixed TE 02:120 03:90 05:60 */
					39 00 00 40 00 00 04 B0 00 2A B9
					39 00 00 40 00 00 03 B9 00 00
					15 00 00 40 00 00 02 F7 0F
					39 00 00 40 00 00 03 F0 A5 A5

					/* 60hz Transition */
					39 00 00 40 00 00 03 F0 5A 5A
					39 00 00 40 00 00 04 B0 00 16 F2
					39 00 00 40 00 00 03 F2 1B 50
					39 00 00 40 00 00 04 B0 00 08 CB				/* power saving */
					15 00 00 40 00 00 02 CB 24
					15 00 00 40 00 00 02 60 01
					39 00 00 40 00 00 03 BD 23 02
					39 00 00 40 00 00 04 B0 00 10 BD
					15 00 00 40 00 00 02 BD 00
					39 00 00 40 00 00 04 B0 00 16 BD
					15 00 00 40 00 00 02 BD 77
					39 00 00 40 00 00 04 B0 00 14 BD
					15 00 00 40 00 00 02 BD 01
					15 00 00 40 00 00 02 F7 0F
					39 00 00 00 00 00 03 F0 A5 A5
				];
				qcom,mdss-dsi-on-command = [
					/* DSC Setting */
					39 00 00 00 00 00 5A 9E 12
					00 00 AB 30 80 09 6C 04 38
					00 24 02 1C 02 1C 02 00 02
					3B 00 20 03 35 00 07 00 0E
					03 34 02 D4 18 00 10 F0 07
					10 20 00 06 0F 0F 33 0E 1C
					2A 38 46 54 62 69 70 77 79
					7B 7D 7E 02 02 22 00 2A 40
					2A BE 3A FC 3A FA 3A F8 3B
					38 3B 78 3B B6 4B B6 4B F4
					4B F4 6C 34 84 74 00
					15 00 00 00 00 00 02 9D 01

					/* Sleep Out(11h) */
					05 00 00 00 06 00 01 11

					/* TSP_SYNC1 Fixed Setting */
					39 00 00 40 00 00 03 F0 5A 5A
					39 00 00 40 00 00 04 B0 00 22 B9
					39 00 00 40 00 00 03 B9 A1 B1
					39 00 00 40 00 00 04 B0 00 3A B9
					15 00 00 40 00 00 02 B9 05						/* TSP_VSYNC Fixed TE 02:120 03:90 05:60 */
					39 00 00 40 00 00 04 B0 00 26 B9
					39 00 00 40 00 00 03 B9 00 00
					15 00 00 40 00 00 02 F7 0F
					39 00 00 00 00 00 03 F0 A5 A5
					/* TSP_SYNC3 Fixed Setting */
					39 00 00 40 00 00 03 F0 5A 5A
					39 00 00 40 00 00 04 B0 00 24 B9
					15 00 00 40 00 00 02 B9 21
					39 00 00 40 00 00 04 B0 00 38 B9
					15 00 00 40 00 00 02 B9 05						/* TSP_VSYNC Fixed TE 02:120 03:90 05:60 */
					39 00 00 40 00 00 04 B0 00 2A B9
					39 00 00 40 00 00 03 B9 00 00
					15 00 00 40 00 00 02 F7 0F
					39 00 00 00 79 00 03 F0 A5 A5

					/* 60hz Transition */
					39 00 00 40 00 00 03 F0 5A 5A
					39 00 00 40 00 00 04 B0 00 16 F2
					39 00 00 40 00 00 03 F2 1B 50
					39 00 00 40 00 00 04 B0 00 08 CB				/* power saving */
					15 00 00 40 00 00 02 CB 24
					15 00 00 40 00 00 02 60 01
					39 00 00 40 00 00 03 BD 23 02
					39 00 00 40 00 00 04 B0 00 10 BD
					15 00 00 40 00 00 02 BD 00
					39 00 00 40 00 00 04 B0 00 16 BD
					15 00 00 40 00 00 02 BD 77
					39 00 00 40 00 00 04 B0 00 14 BD
					15 00 00 40 00 00 02 BD 01
					15 00 00 40 00 00 02 F7 0F
					39 00 00 00 00 00 03 F0 A5 A5

					/* Common Setting */
					39 00 00 40 00 00 03 F0 5A 5A
					39 00 00 40 00 00 03 F2 00 01					/* FQ_CON Setting */
					39 00 00 00 00 00 03 F0 A5 A5
					/* TE(Vsync) ON */
					39 00 00 40 00 00 03 F0 5A 5A
					15 00 00 40 00 00 02 35 00
					15 00 00 40 00 00 02 B9 00
					39 00 00 00 00 00 03 F0 A5 A5
					/* CASET/PASET Setting */
					39 00 00 00 00 00 05 2A 00 00 04 37
					39 00 00 00 00 00 05 2B 00 00 09 6B
					/* Scaler Setting */
					39 00 00 40 00 00 03 F0 5A 5A
					15 00 00 40 00 00 02 C3 89
					39 00 00 40 00 00 04 B0 00 24 C3
					39 00 00 40 00 00 12 C3 FD 00 FD 00 FD 00 FD 00 FD 00 FD 00 FD 00 FD 00 FD
					39 00 00 40 00 00 04 B0 00 3A C3
					39 00 00 40 00 00 12 C3 B0 00 B0 00 B0 00 B0 00 B0 00 B0 00 B0 00 B0 00 B0
					39 00 00 40 00 00 04 B0 00 50 C3
					39 00 00 40 00 00 12 C3 43 00 43 00 43 00 43 00 43 00 43 00 43 00 43 00 43
					39 00 00 40 00 00 04 B0 00 61 C3
					39 00 00 40 00 00 17 C3 CC CC CC CC C0 FE 00 FE 00 FE 00 FE 00 FE 00 FE 00 FE 00 FE 00 FE
					39 00 00 00 00 00 03 F0 A5 A5
					/* Pre-charge time setting */
					39 00 00 40 00 00 03 F0 5A 5A
					39 00 00 40 00 00 04 B0 00 2B F6
					39 00 00 40 00 00 04 F6 60 63 69
					15 00 00 40 00 00 02 F7 0F
					39 00 00 00 00 00 03 F0 A5 A5
					/* HLPM Power Saving */
					39 00 00 40 00 00 03 F0 5A 5A
					39 00 00 40 00 00 04 B0 00 46 F4
					15 00 00 40 00 00 02 F4 08
					39 00 00 00 00 00 03 F0 A5 A5
					/* DCDC setting of AOD Sequence */
					39 00 00 40 00 00 03 F0 5A 5A
					39 00 00 40 00 00 04 B0 00 18 B1
					39 00 00 40 00 00 02 B1 05
					39 00 00 00 00 00 03 F0 A5 A5

					/* Brightness Control */
					39 00 00 40 00 00 03 F0 5A 5A
					39 00 00 40 00 00 04 B0 00 0D 63
					15 00 00 40 00 00 02 63 01						/* Dimming Setting */
					39 00 00 40 00 00 04 B0 00 0C 63
					15 00 00 40 00 00 02 63 20
					39 00 00 00 00 00 03 F0 A5 A5
					15 00 00 00 00 00 02 53 28
					15 00 00 00 00 00 02 F7 0F
					/* ACL Mode */
					39 00 00 40 00 00 03 F0 5A 5A
					15 00 00 40 00 00 02 55 00
					39 00 00 00 00 00 03 F0 A5 A5
					/* OPEC Setting */
					39 00 00 40 00 00 03 F0 5A 5A
					39 00 00 40 00 00 04 B0 00 52 1F
					15 00 00 40 00 00 02 1F 02
					39 00 00 40 00 00 04 B0 00 54 1F
					15 00 00 40 00 00 02 1F 00
					39 00 00 00 00 00 03 F0 A5 A5
				];

				qcom,mdss-dsi-qsync-on-commands = [
				];
				qcom,mdss-dsi-qsync-off-commands = [
					/* SDC Auto Off */
					39 00 00 40 00 00 03 F0 5A 5A
					15 00 00 40 00 00 02 BD 23
					39 00 00 40 00 00 04 B0 00 10 BD
					15 00 00 40 00 00 02 BD 00
					39 00 00 40 00 00 04 B0 00 16 BD
					15 00 00 40 00 00 02 BD 77
					39 00 00 00 00 00 03 F0 A5 A5
				];
				qcom,mdss-dsi-qsync-min-fps-0-command = [
					/* SDC Auto Off */
					39 00 00 40 00 00 03 F0 5A 5A
					39 00 00 40 00 00 04 B0 00 14 BD
					15 00 00 40 00 00 02 BD 00
					15 00 00 40 00 00 02 F7 0F
					39 00 00 00 00 00 03 F0 A5 A5
				];

				qcom,mdss-dsi-qsync-on-commands-state ="dsi_hs_mode";
				qcom,mdss-dsi-qsync-off-commands-state ="dsi_hs_mode";
				qcom,mdss-dsi-qsync-min-fps-0-command-state = "dsi_hs_mode";
				qcom,panel-roi-alignment=<1080 36 1080 36 1080 36>;
				qcom,partial-update-enabled = "single_roi";

				qcom,lm-split = <540 540>;
				qcom,mdss-dsc-slice-height = <36>;
				qcom,mdss-dsc-slice-width = <540>;
			};

			timing@fhd_oplus_120 {
				#include "dsi-panel-samsung-amb670yf07-1440-3216-dsc-cmd-common.dtsi"
				//qcom,mdss-mdp-transfer-time-us = <6000>;
				cell-index = <3>;
				qcom,mdss-dsi-panel-framerate = <120>;
				qcom,mdss-dsi-panel-clockrate = <825600000>;
				qcom,mdss-dsi-panel-width = <1080>;
				qcom,mdss-dsi-panel-height = <2412>;
				qcom,mdss-dsi-h-front-porch = <64>;
				qcom,mdss-dsi-h-back-porch = <54>;
				qcom,mdss-dsi-h-pulse-width = <8>;
				qcom,mdss-dsi-h-sync-pulse = <0>;
				qcom,mdss-dsi-v-back-porch = <8>;
				qcom,mdss-dsi-v-front-porch = <2>;
				qcom,mdss-dsi-v-pulse-width = <2>;

				/* OPLUS ADFR */
				qcom,mdss-dsi-h-sync-skew = <2>;
				qcom,mdss-dsi-qsync-min-fps-0 = <6>;
				qcom,mdss-dsi-qsync-min-fps-1 = <8>;
				qcom,mdss-dsi-qsync-min-fps-2 = <10>;
				qcom,mdss-dsi-qsync-min-fps-3 = <12>;
				qcom,mdss-dsi-qsync-min-fps-4 = <15>;
				qcom,mdss-dsi-qsync-min-fps-5 = <20>;
				qcom,mdss-dsi-qsync-min-fps-6 = <24>;
				qcom,mdss-dsi-qsync-min-fps-7 = <30>;
				qcom,mdss-dsi-qsync-min-fps-8 = <40>;
				qcom,mdss-dsi-qsync-min-fps-9 = <60>;

				qcom,mdss-dsi-timing-switch-command = [
					/* CASET/PASET Setting */
					39 00 00 40 00 00 05 2A 00 00 04 37
					39 00 00 40 00 00 05 2B 00 00 09 6B
					/* Scaler Setting */
					39 00 00 40 00 00 03 F0 5A 5A
					15 00 00 40 00 00 02 C3 89
					39 00 00 40 00 00 04 B0 00 24 C3
					39 00 00 40 00 00 12 C3 FD 00 FD 00 FD 00 FD 00 FD 00 FD 00 FD 00 FD 00 FD
					39 00 00 40 00 00 04 B0 00 3A C3
					39 00 00 40 00 00 12 C3 B0 00 B0 00 B0 00 B0 00 B0 00 B0 00 B0 00 B0 00 B0
					39 00 00 40 00 00 04 B0 00 50 C3
					39 00 00 40 00 00 12 C3 43 00 43 00 43 00 43 00 43 00 43 00 43 00 43 00 43
					39 00 00 40 00 00 04 B0 00 61 C3
					39 00 00 40 00 00 17 C3 CC CC CC CC C0 FE 00 FE 00 FE 00 FE 00 FE 00 FE 00 FE 00 FE 00 FE
					39 00 00 40 00 00 03 F0 A5 A5
					/* OPLUS ADFR OFF */
					39 00 00 40 00 00 03 F0 5A 5A
					39 00 00 40 00 00 03 FC 5A 5A
					15 00 00 40 00 00 02 B9 00						/* TP shift fixed */
					39 00 00 40 00 00 04 B0 00 02 60
					15 00 00 40 00 00 02 60 00						/* OPLUS ADFR OFF */
					39 00 00 40 00 00 03 F2 00 01					/* 0x01,0x00:ADFR ON setting 0x00,0x01:ADFR OFF Setting */
					15 00 00 40 00 00 02 F7 0F
					39 00 00 40 00 00 03 FC A5 A5
					39 00 00 40 00 00 03 F0 A5 A5

					/* TSP_SYNC1 Fixed Setting */
					39 00 00 40 00 00 03 F0 5A 5A
					39 00 00 40 00 00 04 B0 00 22 B9
					39 00 00 40 00 00 03 B9 A1 B1
					39 00 00 40 00 00 04 B0 00 3A B9
					15 00 00 40 00 00 02 B9 02						/* TSP_VSYNC Fixed TE 02:120 03:90 05:60 */
					39 00 00 40 00 00 04 B0 00 26 B9
					39 00 00 40 00 00 03 B9 00 00
					15 00 00 40 00 00 02 F7 0F
					39 00 00 40 00 00 03 F0 A5 A5
					/* TSP_SYNC3 Fixed Setting */
					39 00 00 40 00 00 03 F0 5A 5A
					39 00 00 40 00 00 04 B0 00 24 B9
					15 00 00 40 00 00 02 B9 21
					39 00 00 40 00 00 04 B0 00 38 B9
					15 00 00 40 00 00 02 B9 02						/* TSP_VSYNC Fixed TE 02:120 03:90 05:60 */
					39 00 00 40 00 00 04 B0 00 2A B9
					39 00 00 40 00 00 03 B9 00 00
					15 00 00 40 00 00 02 F7 0F
					39 00 00 40 00 00 03 F0 A5 A5

					/* 120hz Transition */
					39 00 00 40 00 00 03 F0 5A 5A
					39 00 00 40 00 00 04 B0 00 16 F2
					39 00 00 40 00 00 03 F2 1B 50
					39 00 00 40 00 00 04 B0 00 08 CB				/* power saving */
					15 00 00 40 00 00 02 CB 24
					15 00 00 40 00 00 02 60 00
					39 00 00 40 00 00 03 BD 23 02
					39 00 00 40 00 00 04 B0 00 10 BD
					15 00 00 40 00 00 02 BD 00
					39 00 00 40 00 00 04 B0 00 16 BD
					15 00 00 40 00 00 02 BD 77
					39 00 00 40 00 00 04 B0 00 14 BD
					15 00 00 40 00 00 02 BD 00
					15 00 00 40 00 00 02 F7 0F
					39 00 00 00 00 00 03 F0 A5 A5
				];
				qcom,mdss-dsi-on-command = [
					/* DSC Setting */
					39 00 00 00 00 00 5A 9E 12
					00 00 AB 30 80 09 6C 04 38
					00 24 02 1C 02 1C 02 00 02
					3B 00 20 03 35 00 07 00 0E
					03 34 02 D4 18 00 10 F0 07
					10 20 00 06 0F 0F 33 0E 1C
					2A 38 46 54 62 69 70 77 79
					7B 7D 7E 02 02 22 00 2A 40
					2A BE 3A FC 3A FA 3A F8 3B
					38 3B 78 3B B6 4B B6 4B F4
					4B F4 6C 34 84 74 00
					15 00 00 00 00 00 02 9D 01

					/* Sleep Out(11h) */
					05 00 00 00 06 00 01 11

					/* TSP_SYNC1 Fixed Setting */
					39 00 00 40 00 00 03 F0 5A 5A
					39 00 00 40 00 00 04 B0 00 22 B9
					39 00 00 40 00 00 03 B9 A1 B1
					39 00 00 40 00 00 04 B0 00 3A B9
					15 00 00 40 00 00 02 B9 02						/* TSP_VSYNC Fixed TE 02:120 03:90 05:60 */
					39 00 00 40 00 00 04 B0 00 26 B9
					39 00 00 40 00 00 03 B9 00 00
					15 00 00 40 00 00 02 F7 0F
					39 00 00 00 00 00 03 F0 A5 A5
					/* TSP_SYNC3 Fixed Setting */
					39 00 00 40 00 00 03 F0 5A 5A
					39 00 00 40 00 00 04 B0 00 24 B9
					15 00 00 40 00 00 02 B9 21
					39 00 00 40 00 00 04 B0 00 38 B9
					15 00 00 40 00 00 02 B9 02						/* TSP_VSYNC Fixed TE 02:120 03:90 05:60 */
					39 00 00 40 00 00 04 B0 00 2A B9
					39 00 00 40 00 00 03 B9 00 00
					15 00 00 40 00 00 02 F7 0F
					39 00 00 00 79 00 03 F0 A5 A5

					/* 120hz Transition */
					39 00 00 40 00 00 03 F0 5A 5A
					39 00 00 40 00 00 04 B0 00 16 F2
					39 00 00 40 00 00 03 F2 1B 50
					39 00 00 40 00 00 04 B0 00 08 CB				/* power saving */
					15 00 00 40 00 00 02 CB 24
					15 00 00 40 00 00 02 60 00
					39 00 00 40 00 00 03 BD 23 02
					39 00 00 40 00 00 04 B0 00 10 BD
					15 00 00 40 00 00 02 BD 00
					39 00 00 40 00 00 04 B0 00 16 BD
					15 00 00 40 00 00 02 BD 77
					39 00 00 40 00 00 04 B0 00 14 BD
					15 00 00 40 00 00 02 BD 00
					15 00 00 40 00 00 02 F7 0F
					39 00 00 00 00 00 03 F0 A5 A5

					/* Common Setting */
					39 00 00 40 00 00 03 F0 5A 5A
					39 00 00 40 00 00 03 F2 00 01					/* FQ_CON Setting */
					39 00 00 00 00 00 03 F0 A5 A5
					/* TE(Vsync) ON */
					39 00 00 40 00 00 03 F0 5A 5A
					15 00 00 40 00 00 02 35 00
					15 00 00 40 00 00 02 B9 00
					39 00 00 00 00 00 03 F0 A5 A5
					/* CASET/PASET Setting */
					39 00 00 00 00 00 05 2A 00 00 04 37
					39 00 00 00 00 00 05 2B 00 00 09 6B
					/* Scaler Setting */
					39 00 00 40 00 00 03 F0 5A 5A
					15 00 00 40 00 00 02 C3 89
					39 00 00 40 00 00 04 B0 00 24 C3
					39 00 00 40 00 00 12 C3 FD 00 FD 00 FD 00 FD 00 FD 00 FD 00 FD 00 FD 00 FD
					39 00 00 40 00 00 04 B0 00 3A C3
					39 00 00 40 00 00 12 C3 B0 00 B0 00 B0 00 B0 00 B0 00 B0 00 B0 00 B0 00 B0
					39 00 00 40 00 00 04 B0 00 50 C3
					39 00 00 40 00 00 12 C3 43 00 43 00 43 00 43 00 43 00 43 00 43 00 43 00 43
					39 00 00 40 00 00 04 B0 00 61 C3
					39 00 00 40 00 00 17 C3 CC CC CC CC C0 FE 00 FE 00 FE 00 FE 00 FE 00 FE 00 FE 00 FE 00 FE
					39 00 00 00 00 00 03 F0 A5 A5
					/* Pre-charge time setting */
					39 00 00 40 00 00 03 F0 5A 5A
					39 00 00 40 00 00 04 B0 00 2B F6
					39 00 00 40 00 00 04 F6 60 63 69
					15 00 00 40 00 00 02 F7 0F
					39 00 00 00 00 00 03 F0 A5 A5
					/* HLPM Power Saving */
					39 00 00 40 00 00 03 F0 5A 5A
					39 00 00 40 00 00 04 B0 00 46 F4
					15 00 00 40 00 00 02 F4 08
					39 00 00 00 00 00 03 F0 A5 A5
					/* DCDC setting of AOD Sequence */
					39 00 00 40 00 00 03 F0 5A 5A
					39 00 00 40 00 00 04 B0 00 18 B1
					39 00 00 40 00 00 02 B1 05
					39 00 00 00 00 00 03 F0 A5 A5

					/* Brightness Control */
					39 00 00 40 00 00 03 F0 5A 5A
					39 00 00 40 00 00 04 B0 00 0D 63
					15 00 00 40 00 00 02 63 01						/* Dimming Setting */
					39 00 00 40 00 00 04 B0 00 0C 63
					15 00 00 40 00 00 02 63 20
					39 00 00 00 00 00 03 F0 A5 A5
					15 00 00 00 00 00 02 53 28
					15 00 00 00 00 00 02 F7 0F
					/* ACL Mode */
					39 00 00 40 00 00 03 F0 5A 5A
					15 00 00 40 00 00 02 55 00
					39 00 00 00 00 00 03 F0 A5 A5
					/* OPEC Setting */
					39 00 00 40 00 00 03 F0 5A 5A
					39 00 00 40 00 00 04 B0 00 52 1F
					15 00 00 40 00 00 02 1F 02
					39 00 00 40 00 00 04 B0 00 54 1F
					15 00 00 40 00 00 02 1F 00
					39 00 00 00 00 00 03 F0 A5 A5
				];

				qcom,mdss-dsi-qsync-on-commands = [
				];
				qcom,mdss-dsi-qsync-off-commands = [
					39 00 00 40 00 00 03 F0 5A 5A
					39 00 00 40 00 00 04 B0 00 14 BD
					15 00 00 40 00 00 02 BD 00
					15 00 00 40 00 00 02 F7 0F
					39 00 00 00 00 00 03 F0 A5 A5
				];
				qcom,mdss-dsi-qsync-min-fps-0-command = [
					39 00 00 40 00 00 03 F0 5A 5A
					39 00 00 40 00 00 04 B0 00 14 BD
					15 00 00 40 00 00 02 BD 13
					15 00 00 40 00 00 02 F7 0F
					39 00 00 00 00 00 03 F0 A5 A5
				];
				qcom,mdss-dsi-qsync-min-fps-1-command = [
					39 00 00 40 00 00 03 F0 5A 5A
					39 00 00 40 00 00 04 B0 00 14 BD
					15 00 00 40 00 00 02 BD 0E
					15 00 00 40 00 00 02 F7 0F
					39 00 00 00 00 00 03 F0 A5 A5
				];
				qcom,mdss-dsi-qsync-min-fps-2-command = [
					39 00 00 40 00 00 03 F0 5A 5A
					39 00 00 40 00 00 04 B0 00 14 BD
					15 00 00 40 00 00 02 BD 0B
					15 00 00 40 00 00 02 F7 0F
					39 00 00 00 00 00 03 F0 A5 A5
				];
				qcom,mdss-dsi-qsync-min-fps-3-command = [
					39 00 00 40 00 00 03 F0 5A 5A
					39 00 00 40 00 00 04 B0 00 14 BD
					15 00 00 40 00 00 02 BD 09
					15 00 00 40 00 00 02 F7 0F
					39 00 00 00 00 00 03 F0 A5 A5
				];
				qcom,mdss-dsi-qsync-min-fps-4-command = [
					39 00 00 40 00 00 03 F0 5A 5A
					39 00 00 40 00 00 04 B0 00 14 BD
					15 00 00 40 00 00 02 BD 07
					15 00 00 40 00 00 02 F7 0F
					39 00 00 00 00 00 03 F0 A5 A5
				];
				qcom,mdss-dsi-qsync-min-fps-5-command = [
					39 00 00 40 00 00 03 F0 5A 5A
					39 00 00 40 00 00 04 B0 00 14 BD
					15 00 00 40 00 00 02 BD 05
					15 00 00 40 00 00 02 F7 0F
					39 00 00 00 00 00 03 F0 A5 A5
				];
				qcom,mdss-dsi-qsync-min-fps-6-command = [
					39 00 00 40 00 00 03 F0 5A 5A
					39 00 00 40 00 00 04 B0 00 14 BD
					15 00 00 40 00 00 02 BD 04
					15 00 00 40 00 00 02 F7 0F
					39 00 00 00 00 00 03 F0 A5 A5
				];
				qcom,mdss-dsi-qsync-min-fps-7-command = [
					39 00 00 40 00 00 03 F0 5A 5A
					39 00 00 40 00 00 04 B0 00 14 BD
					15 00 00 40 00 00 02 BD 03
					15 00 00 40 00 00 02 F7 0F
					39 00 00 00 00 00 03 F0 A5 A5
				];
				qcom,mdss-dsi-qsync-min-fps-8-command = [
					39 00 00 40 00 00 03 F0 5A 5A
					39 00 00 40 00 00 04 B0 00 14 BD
					15 00 00 40 00 00 02 BD 02
					15 00 00 40 00 00 02 F7 0F
					39 00 00 00 00 00 03 F0 A5 A5
				];
				qcom,mdss-dsi-qsync-min-fps-9-command = [
					39 00 00 40 00 00 03 F0 5A 5A
					39 00 00 40 00 00 04 B0 00 14 BD
					15 00 00 40 00 00 02 BD 01
					15 00 00 40 00 00 02 F7 0F
					39 00 00 00 00 00 03 F0 A5 A5
				];

				qcom,mdss-dsi-qsync-on-commands-state ="dsi_hs_mode";
				qcom,mdss-dsi-qsync-off-commands-state ="dsi_hs_mode";
				qcom,mdss-dsi-qsync-min-fps-0-command-state = "dsi_hs_mode";
				qcom,mdss-dsi-qsync-min-fps-1-command-state = "dsi_hs_mode";
				qcom,mdss-dsi-qsync-min-fps-2-command-state = "dsi_hs_mode";
				qcom,mdss-dsi-qsync-min-fps-3-command-state = "dsi_hs_mode";
				qcom,mdss-dsi-qsync-min-fps-4-command-state = "dsi_hs_mode";
				qcom,mdss-dsi-qsync-min-fps-5-command-state = "dsi_hs_mode";
				qcom,mdss-dsi-qsync-min-fps-6-command-state = "dsi_hs_mode";
				qcom,mdss-dsi-qsync-min-fps-7-command-state = "dsi_hs_mode";
				qcom,mdss-dsi-qsync-min-fps-8-command-state = "dsi_hs_mode";
				qcom,mdss-dsi-qsync-min-fps-9-command-state = "dsi_hs_mode";
				qcom,panel-roi-alignment=<1080 36 1080 36 1080 36>;
				qcom,partial-update-enabled = "single_roi";

				qcom,lm-split = <540 540>;
				qcom,mdss-dsc-slice-height = <36>;
				qcom,mdss-dsc-slice-width = <540>;
			};

			timing@wqhd_sdc_60 {
				#include "dsi-panel-samsung-amb670yf07-1440-3216-dsc-60fps-cmd-common.dtsi"
				cell-index = <4>;
				qcom,mdss-mdp-transfer-time-us = <7700>;
				qcom,mdss-dsi-panel-framerate = <60>;
				qcom,mdss-dsi-panel-clockrate = <1372000000>;
				qcom,mdss-dsi-panel-width = <1440>;
				qcom,mdss-dsi-panel-height = <3216>;
				qcom,mdss-dsi-h-front-porch = <88>;
				qcom,mdss-dsi-h-back-porch = <56>;
				qcom,mdss-dsi-h-pulse-width = <8>;
				qcom,mdss-dsi-h-sync-pulse = <0>;
				qcom,mdss-dsi-v-back-porch = <8>;
				qcom,mdss-dsi-v-front-porch = <8>;
				qcom,mdss-dsi-v-pulse-width = <8>;

				/* SDC MFR */
				qcom,mdss-dsi-h-sync-skew = <1>;
				qcom,mdss-dsi-panel-vsync-source = <1>;
				qcom,mdss-dsi-qsync-min-fps-0 = <1314>;

				qcom,mdss-dsi-timing-switch-command = [
					/* CASET/PASET Setting */
					39 00 00 40 00 00 05 2A 00 00 05 9F
					39 00 00 40 00 00 05 2B 00 00 0C 8F
					/* Scaler Setting */
					39 00 00 40 00 00 03 F0 5A 5A
					15 00 00 40 00 00 02 C3 00
					39 00 00 40 00 00 03 F0 A5 A5

					/* OPLUS ADFR OFF */
					39 00 00 40 00 00 03 F0 5A 5A
					39 00 00 40 00 00 03 FC 5A 5A
					15 00 00 40 00 00 02 B9 00						/* TP shift fixed */
					39 00 00 40 00 00 04 B0 00 02 60
					15 00 00 40 00 00 02 60 00						/* OPLUS ADFR OFF */
					39 00 00 40 00 00 03 F2 00 01					/* 0x01,0x00:ADFR ON setting 0x00,0x01:ADFR OFF Setting */
					15 00 00 40 00 00 02 F7 0F
					39 00 00 40 00 00 03 FC A5 A5
					39 00 00 40 00 00 03 F0 A5 A5

					/* TSP_SYNC1 Fixed Setting */
					39 00 00 40 00 00 03 F0 5A 5A
					39 00 00 40 00 00 04 B0 00 22 B9
					39 00 00 40 00 00 03 B9 A1 B1
					39 00 00 40 00 00 04 B0 00 3A B9
					15 00 00 40 00 00 02 B9 05						/* TSP_VSYNC Fixed TE 02:120 03:90 05:60 */
					39 00 00 40 00 00 04 B0 00 26 B9
					39 00 00 40 00 00 03 B9 00 00
					15 00 00 40 00 00 02 F7 0F
					39 00 00 40 00 00 03 F0 A5 A5
					/* TSP_SYNC3 Fixed Setting */
					39 00 00 40 00 00 03 F0 5A 5A
					39 00 00 40 00 00 04 B0 00 24 B9
					15 00 00 40 00 00 02 B9 21
					39 00 00 40 00 00 04 B0 00 38 B9
					15 00 00 40 00 00 02 B9 05						/* TSP_VSYNC Fixed TE 02:120 03:90 05:60 */
					39 00 00 40 00 00 04 B0 00 2A B9
					39 00 00 40 00 00 03 B9 00 00
					15 00 00 40 00 00 02 F7 0F
					39 00 00 40 00 00 03 F0 A5 A5

					/* 60hz Transition */
					39 00 00 40 00 00 03 F0 5A 5A
					39 00 00 40 00 00 04 B0 00 16 F2
					39 00 00 40 00 00 03 F2 1B 50
					39 00 00 40 00 00 04 B0 00 08 CB				/* power saving */
					15 00 00 40 00 00 02 CB 24
					15 00 00 40 00 00 02 60 01
					39 00 00 40 00 00 03 BD 23 02
					39 00 00 40 00 00 04 B0 00 10 BD
					15 00 00 40 00 00 02 BD 00
					39 00 00 40 00 00 04 B0 00 16 BD
					15 00 00 40 00 00 02 BD 77
					39 00 00 40 00 00 04 B0 00 14 BD
					15 00 00 40 00 00 02 BD 01
					15 00 00 40 00 00 02 F7 0F
					39 00 00 00 00 00 03 F0 A5 A5
				];
				qcom,mdss-dsi-on-command = [
					/* DSC Setting */
					39 00 00 00 00 00 5A 9E 12
					00 00 AB 30 80 0C 90 05 A0
					00 18 02 D0 02 D0 02 00 02
					86 00 20 02 83 00 0A 00 0D
					04 86 03 2E 18 00 10 F0 07
					10 20 00 06 0F 0F 33 0E 1C
					2A 38 46 54 62 69 70 77 79
					7B 7D 7E 02 02 22 00 2A 40
					2A BE 3A FC 3A FA 3A F8 3B
					38 3B 78 3B B6 4B B6 4B F4
					4B F4 6C 34 84 74 00
					15 00 00 00 00 00 02 9D 01

					/* Sleep Out(11h) */
					05 00 00 00 06 00 01 11

					/* TSP_SYNC1 Fixed Setting */
					39 00 00 40 00 00 03 F0 5A 5A
					39 00 00 40 00 00 04 B0 00 22 B9
					39 00 00 40 00 00 03 B9 A1 B1
					39 00 00 40 00 00 04 B0 00 3A B9
					15 00 00 40 00 00 02 B9 05						/* TSP_VSYNC Fixed TE 02:120 03:90 05:60 */
					39 00 00 40 00 00 04 B0 00 26 B9
					39 00 00 40 00 00 03 B9 00 00
					15 00 00 40 00 00 02 F7 0F
					39 00 00 00 00 00 03 F0 A5 A5
					/* TSP_SYNC3 Fixed Setting */
					39 00 00 40 00 00 03 F0 5A 5A
					39 00 00 40 00 00 04 B0 00 24 B9
					15 00 00 40 00 00 02 B9 21
					39 00 00 40 00 00 04 B0 00 38 B9
					15 00 00 40 00 00 02 B9 05						/* TSP_VSYNC Fixed TE 02:120 03:90 05:60 */
					39 00 00 40 00 00 04 B0 00 2A B9
					39 00 00 40 00 00 03 B9 00 00
					15 00 00 40 00 00 02 F7 0F
					39 00 00 00 79 00 03 F0 A5 A5

					/* 60hz Transition */
					39 00 00 40 00 00 03 F0 5A 5A
					39 00 00 40 00 00 04 B0 00 16 F2
					39 00 00 40 00 00 03 F2 1B 50
					39 00 00 40 00 00 04 B0 00 08 CB				/* power saving */
					15 00 00 40 00 00 02 CB 24
					15 00 00 40 00 00 02 60 01
					39 00 00 40 00 00 03 BD 23 02
					39 00 00 40 00 00 04 B0 00 10 BD
					15 00 00 40 00 00 02 BD 00
					39 00 00 40 00 00 04 B0 00 16 BD
					15 00 00 40 00 00 02 BD 77
					39 00 00 40 00 00 04 B0 00 14 BD
					15 00 00 40 00 00 02 BD 01
					15 00 00 40 00 00 02 F7 0F
					39 00 00 00 00 00 03 F0 A5 A5

					/* Common Setting */
					39 00 00 40 00 00 03 F0 5A 5A
					39 00 00 40 00 00 03 F2 00 01					/* FQ_CON Setting */
					39 00 00 00 00 00 03 F0 A5 A5
					/* TE(Vsync) ON */
					39 00 00 40 00 00 03 F0 5A 5A
					15 00 00 40 00 00 02 35 00
					15 00 00 40 00 00 02 B9 00
					39 00 00 00 00 00 03 F0 A5 A5
					/* CASET/PASET Setting */
					39 00 00 00 00 00 05 2A 00 00 05 9F
					39 00 00 00 00 00 05 2B 00 00 0C 8F
					/* Scaler Setting */
					39 00 00 40 00 00 03 F0 5A 5A
					15 00 00 40 00 00 02 C3 00
					39 00 00 00 00 00 03 F0 A5 A5
					/* Pre-charge time setting */
					39 00 00 40 00 00 03 F0 5A 5A
					39 00 00 40 00 00 04 B0 00 2B F6
					39 00 00 40 00 00 04 F6 60 63 69
					15 00 00 40 00 00 02 F7 0F
					39 00 00 00 00 00 03 F0 A5 A5
					/* HLPM Power Saving */
					39 00 00 40 00 00 03 F0 5A 5A
					39 00 00 40 00 00 04 B0 00 46 F4
					15 00 00 40 00 00 02 F4 08
					39 00 00 00 00 00 03 F0 A5 A5
					/* DCDC setting of AOD Sequence */
					39 00 00 40 00 00 03 F0 5A 5A
					39 00 00 40 00 00 04 B0 00 18 B1
					39 00 00 40 00 00 02 B1 05
					39 00 00 00 00 00 03 F0 A5 A5

					/* Brightness Control */
					39 00 00 40 00 00 03 F0 5A 5A
					39 00 00 40 00 00 04 B0 00 0D 63
					15 00 00 40 00 00 02 63 01						/* Dimming Setting */
					39 00 00 40 00 00 04 B0 00 0C 63
					15 00 00 40 00 00 02 63 20
					39 00 00 00 00 00 03 F0 A5 A5
					15 00 00 00 00 00 02 53 28
					15 00 00 00 00 00 02 F7 0F
					/* ACL Mode */
					39 00 00 40 00 00 03 F0 5A 5A
					15 00 00 40 00 00 02 55 00
					39 00 00 00 00 00 03 F0 A5 A5
					/* OPEC Setting */
					39 00 00 40 00 00 03 F0 5A 5A
					39 00 00 40 00 00 04 B0 00 52 1F
					15 00 00 40 00 00 02 1F 02
					39 00 00 40 00 00 04 B0 00 54 1F
					15 00 00 40 00 00 02 1F 00
					39 00 00 00 00 00 03 F0 A5 A5
				];

				qcom,mdss-dsi-qsync-on-commands = [
				];
				qcom,mdss-dsi-qsync-off-commands = [
					/* SDC Auto Off */
					39 00 00 40 00 00 03 F0 5A 5A
					15 00 00 40 00 00 02 BD 23
					39 00 00 40 00 00 04 B0 00 10 BD
					15 00 00 40 00 00 02 BD 00
					39 00 00 40 00 00 04 B0 00 16 BD
					15 00 00 40 00 00 02 BD 77
					39 00 00 00 00 00 03 F0 A5 A5
				];
				qcom,mdss-dsi-qsync-min-fps-0-command = [
					/* SDC Auto Off */
					39 00 00 40 00 00 03 F0 5A 5A
					39 00 00 40 00 00 04 B0 00 14 BD
					15 00 00 40 00 00 02 BD 00
					15 00 00 40 00 00 02 F7 0F
					39 00 00 00 00 00 03 F0 A5 A5
				];

				qcom,mdss-dsi-qsync-on-commands-state ="dsi_hs_mode";
				qcom,mdss-dsi-qsync-off-commands-state ="dsi_hs_mode";
				qcom,mdss-dsi-qsync-min-fps-0-command-state = "dsi_hs_mode";
				qcom,panel-roi-alignment=<1440 24 1440 24 1440 24>;
				qcom,partial-update-enabled = "single_roi";

				qcom,lm-split = <720 720>;
				qcom,mdss-dsc-slice-height = <24>;
				qcom,mdss-dsc-slice-width = <720>;
			};

			timing@wqhd_sdc_90 {
				cell-index = <5>;
				qcom,mdss-mdp-transfer-time-us = <7700>;
				qcom,mdss-dsi-panel-framerate = <90>;
				qcom,mdss-dsi-panel-clockrate = <1372000000>;
				qcom,mdss-dsi-panel-width = <1440>;
				qcom,mdss-dsi-panel-height = <3216>;
				qcom,mdss-dsi-h-front-porch = <88>;
				qcom,mdss-dsi-h-back-porch = <58>;
				qcom,mdss-dsi-h-pulse-width = <8>;
				qcom,mdss-dsi-h-sync-pulse = <0>;
				qcom,mdss-dsi-v-back-porch = <8>;
				qcom,mdss-dsi-v-front-porch = <8>;
				qcom,mdss-dsi-v-pulse-width = <8>;
				qcom,mdss-dsi-h-left-border = <0>;
				qcom,mdss-dsi-h-right-border = <0>;
				qcom,mdss-dsi-v-top-border = <0>;
				qcom,mdss-dsi-v-bottom-border = <0>;
				qcom,mdss-dsi-panel-jitter = <0x4 0x1>;

				/* ofp config */
				oplus,ofp-need-to-separate-backlight;
				oplus,ofp-hbm-on-period = <2>;

				/* SDC ADFR */
				qcom,mdss-dsi-h-sync-skew = <0>;
				qcom,mdss-dsi-panel-vsync-source = <1>;
				oplus,adfr-fakeframe-config = <3>;
				oplus,adfr-fakeframe-deferred-time = <8>;		/* period*0.7 */
				qcom,mdss-dsi-qsync-min-fps-0 = <1314>;
				qcom,mdss-dsi-qsync-min-fps-1 = <1314>;
				qcom,mdss-dsi-fakeframe-command = [
					05 00 00 40 00 00 01 2C
					05 00 00 40 00 00 01 3C
					05 00 00 40 00 00 01 2C
					05 00 00 40 00 00 01 3C
					05 00 00 00 00 00 01 00
				];
				qcom,mdss-dsi-adfr-pre-switch-command = [
					39 00 00 40 00 00 03 F0 5A 5A					/* Level2 key Access Enable */
					39 00 00 40 00 00 04 B0 00 14 BD
					15 00 00 40 00 00 02 BD 00						/* SDC auto mode min == max */
					15 00 00 40 00 00 02 BD 23						/* 21 : Manual On  23 Auto On */
					15 00 00 40 00 00 02 F7 0F
					39 00 00 00 00 00 03 F0 A5 A5					/* Level2 key Access Disable */
				];

				qcom,mdss-dsi-timing-switch-command = [
					/* CASET/PASET Setting */
					39 00 00 40 00 00 05 2A 00 00 05 9F
					39 00 00 40 00 00 05 2B 00 00 0C 8F
					/* Scaler Setting */
					39 00 00 40 00 00 03 F0 5A 5A
					15 00 00 40 00 00 02 C3 00
					39 00 00 40 00 00 03 F0 A5 A5

					/* OPLUS ADFR OFF */
					39 00 00 40 00 00 03 F0 5A 5A
					39 00 00 40 00 00 03 FC 5A 5A
					15 00 00 40 00 00 02 B9 00						/* TP shift fixed */
					39 00 00 40 00 00 04 B0 00 02 60
					15 00 00 40 00 00 02 60 00						/* OPLUS ADFR OFF */
					39 00 00 40 00 00 03 F2 00 01					/* 0x01,0x00:ADFR ON setting 0x00,0x01:ADFR OFF Setting */
					15 00 00 40 00 00 02 F7 0F
					39 00 00 40 00 00 03 FC A5 A5
					39 00 00 40 00 00 03 F0 A5 A5

					/* TSP_SYNC1 Fixed Setting */
					39 00 00 40 00 00 03 F0 5A 5A
					39 00 00 40 00 00 04 B0 00 22 B9
					39 00 00 40 00 00 03 B9 A1 B1
					39 00 00 40 00 00 04 B0 00 3A B9
					15 00 00 40 00 00 02 B9 03						/* TSP_VSYNC Fixed TE 02:120 03:90 05:60 */
					39 00 00 40 00 00 04 B0 00 26 B9
					39 00 00 40 00 00 03 B9 00 00
					15 00 00 40 00 00 02 F7 0F
					39 00 00 40 00 00 03 F0 A5 A5
					/* TSP_SYNC3 Fixed Setting */
					39 00 00 40 00 00 03 F0 5A 5A
					39 00 00 40 00 00 04 B0 00 24 B9
					15 00 00 40 00 00 02 B9 21
					39 00 00 40 00 00 04 B0 00 38 B9
					15 00 00 40 00 00 02 B9 03						/* TSP_VSYNC Fixed TE 02:120 03:90 05:60 */
					39 00 00 40 00 00 04 B0 00 2A B9
					39 00 00 40 00 00 03 B9 00 00
					15 00 00 40 00 00 02 F7 0F
					39 00 00 40 00 00 03 F0 A5 A5

					/* 90hz Transition */
					39 00 00 40 00 00 03 F0 5A 5A
					39 00 00 40 00 00 04 B0 00 16 F2
					39 00 00 40 00 00 03 F2 1B 50
					39 00 00 40 00 00 04 B0 00 08 CB				/* power saving */
					15 00 00 40 00 00 02 CB A4
					39 00 00 40 00 00 03 BD 21 82
					15 00 00 40 00 00 02 60 09
					39 00 00 40 00 00 04 B0 00 10 BD
					15 00 00 40 00 00 02 BD 00
					15 00 00 40 00 00 02 F7 0F
					39 00 00 00 00 00 03 F0 A5 A5
				];
				qcom,mdss-dsi-on-command = [
					/* DSC Setting */
					39 00 00 00 00 00 5A 9E 12
					00 00 AB 30 80 0C 90 05 A0
					00 18 02 D0 02 D0 02 00 02
					86 00 20 02 83 00 0A 00 0D
					04 86 03 2E 18 00 10 F0 07
					10 20 00 06 0F 0F 33 0E 1C
					2A 38 46 54 62 69 70 77 79
					7B 7D 7E 02 02 22 00 2A 40
					2A BE 3A FC 3A FA 3A F8 3B
					38 3B 78 3B B6 4B B6 4B F4
					4B F4 6C 34 84 74 00
					15 00 00 00 00 00 02 9D 01

					/* Sleep Out(11h) */
					05 00 00 00 06 00 01 11

					/* TSP_SYNC1 Fixed Setting */
					39 00 00 40 00 00 03 F0 5A 5A
					39 00 00 40 00 00 04 B0 00 22 B9
					39 00 00 40 00 00 03 B9 A1 B1
					39 00 00 40 00 00 04 B0 00 3A B9
					15 00 00 40 00 00 02 B9 03						/* TSP_VSYNC Fixed TE 02:120 03:90 05:60 */
					39 00 00 40 00 00 04 B0 00 26 B9
					39 00 00 40 00 00 03 B9 00 00
					15 00 00 40 00 00 02 F7 0F
					39 00 00 00 00 00 03 F0 A5 A5
					/* TSP_SYNC3 Fixed Setting */
					39 00 00 40 00 00 03 F0 5A 5A
					39 00 00 40 00 00 04 B0 00 24 B9
					15 00 00 40 00 00 02 B9 21
					39 00 00 40 00 00 04 B0 00 38 B9
					15 00 00 40 00 00 02 B9 03						/* TSP_VSYNC Fixed TE 02:120 03:90 05:60 */
					39 00 00 40 00 00 04 B0 00 2A B9
					39 00 00 40 00 00 03 B9 00 00
					15 00 00 40 00 00 02 F7 0F
					39 00 00 00 79 00 03 F0 A5 A5

					/* 90hz Transition */
					39 00 00 40 00 00 03 F0 5A 5A
					39 00 00 40 00 00 04 B0 00 16 F2
					39 00 00 40 00 00 03 F2 1B 50
					39 00 00 40 00 00 04 B0 00 08 CB				/* power saving */
					15 00 00 40 00 00 02 CB A4
					39 00 00 40 00 00 03 BD 21 82
					15 00 00 40 00 00 02 60 09
					39 00 00 40 00 00 04 B0 00 10 BD
					15 00 00 40 00 00 02 BD 00
					15 00 00 40 00 00 02 F7 0F
					39 00 00 00 00 00 03 F0 A5 A5

					/* Common Setting */
					39 00 00 40 00 00 03 F0 5A 5A
					39 00 00 40 00 00 03 F2 00 01					/* FQ_CON Setting */
					39 00 00 00 00 00 03 F0 A5 A5
					/* TE(Vsync) ON */
					39 00 00 40 00 00 03 F0 5A 5A
					15 00 00 40 00 00 02 35 00
					15 00 00 40 00 00 02 B9 00
					39 00 00 00 00 00 03 F0 A5 A5
					/* CASET/PASET Setting */
					39 00 00 00 00 00 05 2A 00 00 05 9F
					39 00 00 00 00 00 05 2B 00 00 0C 8F
					/* Scaler Setting */
					39 00 00 40 00 00 03 F0 5A 5A
					15 00 00 40 00 00 02 C3 00
					39 00 00 00 00 00 03 F0 A5 A5
					/* Pre-charge time setting */
					39 00 00 40 00 00 03 F0 5A 5A
					39 00 00 40 00 00 04 B0 00 2B F6
					39 00 00 40 00 00 04 F6 60 63 69
					15 00 00 40 00 00 02 F7 0F
					39 00 00 00 00 00 03 F0 A5 A5
					/* HLPM Power Saving */
					39 00 00 40 00 00 03 F0 5A 5A
					39 00 00 40 00 00 04 B0 00 46 F4
					15 00 00 40 00 00 02 F4 08
					39 00 00 00 00 00 03 F0 A5 A5
					/* DCDC setting of AOD Sequence */
					39 00 00 40 00 00 03 F0 5A 5A
					39 00 00 40 00 00 04 B0 00 18 B1
					39 00 00 40 00 00 02 B1 05
					39 00 00 00 00 00 03 F0 A5 A5

					/* Brightness Control */
					39 00 00 40 00 00 03 F0 5A 5A
					39 00 00 40 00 00 04 B0 00 0D 63
					15 00 00 40 00 00 02 63 01						/* Dimming Setting */
					39 00 00 40 00 00 04 B0 00 0C 63
					15 00 00 40 00 00 02 63 20
					39 00 00 00 00 00 03 F0 A5 A5
					15 00 00 00 00 00 02 53 28
					15 00 00 00 00 00 02 F7 0F
					/* ACL Mode */
					39 00 00 40 00 00 03 F0 5A 5A
					15 00 00 40 00 00 02 55 00
					39 00 00 00 00 00 03 F0 A5 A5
					/* OPEC Setting */
					39 00 00 40 00 00 03 F0 5A 5A
					39 00 00 40 00 00 04 B0 00 52 1F
					15 00 00 40 00 00 02 1F 02
					39 00 00 40 00 00 04 B0 00 54 1F
					15 00 00 40 00 00 02 1F 00
					39 00 00 00 00 00 03 F0 A5 A5
				];
				qcom,mdss-dsi-post-on-backlight = [
					/* Display On */
					05 00 00 00 00 00 01 29
				];
				qcom,mdss-dsi-off-command = [
					/* Display Off */
					05 00 00 00 15 00 02 28 00
					/* Sleep In */
					05 00 00 00 65 00 02 10 00
				];

				qcom,mdss-dsi-qsync-on-commands = [
				];
				qcom,mdss-dsi-qsync-off-commands = [
				];
				qcom,mdss-dsi-qsync-min-fps-0-command = [
				];
				qcom,mdss-dsi-qsync-min-fps-1-command = [
				];

				qcom,mdss-dsi-hbm-enter-switch-command = [
					/* HBM Mode ON */
					15 00 00 40 00 00 02 53 E0
					39 00 00 00 00 00 03 51 0D D2
				];
				qcom,mdss-dsi-hbm-exit-switch-command = [
					/* HBM Mode OFF */
					15 00 00 40 00 00 02 53 20
					39 00 00 00 00 00 03 51 07 FF
				];

				qcom,mdss-dsi-hbm-on-command = [
					39 00 00 40 00 00 03 F0 5A 5A
					39 00 00 00 0B 00 03 F0 A5 A5
					/* HBM Mode ON */
					15 00 00 40 00 00 02 53 E0
					39 00 00 00 0B 00 03 51 0E FF
					/* AID Cycle + AOR Change Setting */
					39 00 00 40 00 00 03 F0 5A 5A
					39 00 00 40 00 00 04 B0 00 01 BD
					15 00 00 40 00 00 02 BD 02
					39 00 00 40 00 00 04 B0 02 B9 65
					39 00 00 40 00 00 07 65 00 AC 00 AC 00 AC
					15 00 00 40 00 00 02 F7 0F
					39 00 00 00 00 00 03 F0 A5 A5
				];
				qcom,mdss-dsi-hbm-off-command = [
					/* HBM Mode OFF */
					15 00 00 40 00 00 02 53 28
					39 00 00 00 0B 00 03 51 06 9F
					/* AID Cycle + AOR Change Setting */
					39 00 00 40 00 00 03 F0 5A 5A
					39 00 00 40 00 00 04 B0 00 01 BD
					15 00 00 40 00 00 02 BD 02
					39 00 00 40 00 00 04 B0 02 B9 65
					39 00 00 40 00 00 07 65 01 5E 01 5E 01 5E
					15 00 00 40 00 00 02 F7 0F
					39 00 00 00 00 00 03 F0 A5 A5
				];
				qcom,mdss-dsi-lp1-command = [
					05 00 00 00 0C 00 01 28
					/* AOD Mode ON */
					39 00 00 40 00 00 03 F0 5A 5A
					15 00 00 40 00 00 02 53 24
					39 00 00 00 00 00 03 F0 A5 A5
				];
				qcom,mdss-dsi-nolp-command = [
					05 00 00 00 0C 00 01 28
					/* AOD Mode OFF */
					39 00 00 40 00 00 03 F0 5A 5A
					15 00 00 40 00 00 02 53 28
					39 00 00 40 00 00 03 51 00 00
					39 00 00 00 0C 00 03 F0 A5 A5
					05 00 00 00 00 00 01 29
				];
				qcom,mdss-dsi-aod-high-mode-command = [
					/* AOD High Mode, 50nit */
					39 00 00 40 00 00 03 F0 5A 5A
					15 00 00 40 00 00 02 53 24
					39 00 00 00 00 00 03 F0 A5 A5
				];
				qcom,mdss-dsi-aod-low-mode-command = [
					/* AOD Low Mode 10nit */
					39 00 00 40 00 00 03 F0 5A 5A
					15 00 00 40 00 00 02 53 27
					39 00 00 40 00 00 04 B0 03 55 65
					39 00 00 40 00 00 03 65 14 40
					39 00 00 00 00 00 03 F0 A5 A5
				];
				qcom,mdss-dsi-ultra-low-power-aod-on-command = [
					39 00 00 40 00 00 03 F0 5A 5A
					39 00 00 40 00 00 04 B0 00 01 60
					15 00 00 40 00 00 02 60 05
					15 00 00 40 00 00 02 F7 0F
					39 00 00 00 00 00 03 F0 A5 A5
				];
				qcom,mdss-dsi-ultra-low-power-aod-off-command = [
					39 00 00 40 00 00 03 F0 5A 5A
					39 00 00 40 00 00 04 B0 00 01 60
					15 00 00 40 00 00 02 60 00
					15 00 00 40 00 00 02 F7 0F
					39 00 00 00 24 00 03 F0 A5 A5
				];

				qcom,mdss-dsi-loading-effect-1-command = [
					39 00 00 40 00 00 03 F0 5A 5A
					39 00 00 40 00 00 04 B0 02 B6 1D
					15 00 00 40 00 00 02 1D 27
					39 00 00 40 00 00 04 B0 02 B7 1D
					39 00 00 40 00 00 04 1D F9 03 6C
					39 00 00 40 00 00 04 B0 02 C2 1D
					39 00 00 40 00 00 0A 1D 43 4C 82 0A 0B 09 27 2A 24
					39 00 00 40 00 00 04 B0 02 CC 1D
					39 00 00 40 00 00 09 1D 38 30 3E 43 39 41 46 3C
					39 00 00 40 00 00 04 B0 01 A5 1F
					39 00 00 40 00 00 09 1F E2 00 00 00 92 2C 6A 80
					39 00 00 40 00 00 04 B0 01 AD 1F
					39 00 00 40 00 00 07 1F 00 00 00 00 FF 90
					39 00 00 40 00 00 04 B0 01 B5 1F
					39 00 00 40 00 00 04 1F 49 00 10
					39 00 00 40 00 00 04 B0 01 BA 1F
					39 00 00 40 00 00 06 1F 05 FF 10 00 00
					39 00 00 40 00 00 04 B0 01 C1 1F
					39 00 00 40 00 00 05 1F 00 00 00 00
					39 00 00 40 00 00 04 B0 01 C5 1F
					39 00 00 40 00 00 05 1F 03 FF 21 3C
					39 00 00 00 00 00 03 F0 A5 A5
				];
				qcom,mdss-dsi-loading-effect-2-command = [
					39 00 00 40 00 00 03 F0 5A 5A
					39 00 00 40 00 00 04 B0 02 B6 1D
					15 00 00 40 00 00 02 1D 27
					39 00 00 40 00 00 04 B0 02 B7 1D
					39 00 00 40 00 00 04 1D F9 03 6C
					39 00 00 40 00 00 04 B0 02 C2 1D
					39 00 00 40 00 00 0A 1D 43 4C 82 0A 0B 09 27 2A 24
					39 00 00 40 00 00 04 B0 02 CC 1D
					39 00 00 40 00 00 09 1D 38 30 3E 43 39 41 46 3C
					39 00 00 40 00 00 04 B0 01 A5 1F
					39 00 00 40 00 00 09 1F E2 00 00 00 92 2C 6A 80
					39 00 00 40 00 00 04 B0 01 AD 1F
					39 00 00 40 00 00 07 1F 7D 64 7E 65 FF 90
					39 00 00 40 00 00 04 B0 01 B5 1F
					39 00 00 40 00 00 04 1F 49 00 10
					39 00 00 40 00 00 04 B0 01 BA 1F
					39 00 00 40 00 00 06 1F 05 FF 10 00 00
					39 00 00 40 00 00 04 B0 01 C1 1F
					39 00 00 40 00 00 05 1F 00 00 00 00
					39 00 00 40 00 00 04 B0 01 C5 1F
					39 00 00 40 00 00 05 1F 03 FF 21 3C
					39 00 00 00 00 00 03 F0 A5 A5
				];
				qcom,mdss-dsi-loading-effect-off-command = [
					39 00 00 40 00 00 03 F0 5A 5A
					39 00 00 40 00 00 04 B0 02 B6 1D
					15 00 00 40 00 00 02 1D 07
					39 00 00 40 00 00 04 B0 02 B7 1D
					39 00 00 40 00 00 04 1D F9 03 6C
					39 00 00 40 00 00 04 B0 02 C2 1D
					39 00 00 40 00 00 0A 1D 43 4C 82 0A 0B 09 27 2A 24
					39 00 00 40 00 00 04 B0 02 CC 1D
					39 00 00 40 00 00 09 1D 38 30 3E 43 39 41 46 3C
					39 00 00 40 00 00 04 B0 01 A5 1F
					39 00 00 40 00 00 09 1F E2 00 00 00 92 2C 6A 80
					39 00 00 40 00 00 04 B0 01 AD 1F
					39 00 00 40 00 00 07 1F 61 1A 64 1D FF 9F
					39 00 00 40 00 00 04 B0 01 B5 1F
					39 00 00 40 00 00 04 1F 49 00 10
					39 00 00 40 00 00 04 B0 01 BA 1F
					39 00 00 40 00 00 06 1F 05 FF 10 00 00
					39 00 00 40 00 00 04 B0 01 C1 1F
					39 00 00 40 00 00 05 1F 00 00 00 00
					39 00 00 40 00 00 04 B0 01 C5 1F
					39 00 00 40 00 00 05 1F 03 FF 21 3C
					39 00 00 00 00 00 03 F0 A5 A5
				];

				qcom,mdss-dsi-panel-read-register-open-command = [
					39 00 00 00 00 00 03 F0 5A 5A
				];
				qcom,mdss-dsi-panel-id1-command = [
					06 00 00 00 00 00 01 E9
				];
				qcom,mdss-dsi-panel-read-register-close-command = [
					39 00 00 00 00 00 03 F0 A5 A5
				];

				qcom,mdss-dsi-fakeframe-command-state = "dsi_hs_mode";
				qcom,mdss-dsi-adfr-pre-switch-command-state = "dsi_hs_mode";
				qcom,mdss-dsi-timing-switch-command-state = "dsi_hs_mode";
				qcom,mdss-dsi-qsync-on-commands-state ="dsi_hs_mode";
				qcom,mdss-dsi-qsync-off-commands-state ="dsi_hs_mode";
				qcom,mdss-dsi-qsync-min-fps-0-command-state = "dsi_hs_mode";
				qcom,mdss-dsi-qsync-min-fps-1-command-state = "dsi_hs_mode";
				qcom,mdss-dsi-hbm-enter-switch-command-state = "dsi_hs_mode";
				qcom,mdss-dsi-hbm-exit-switch-command-state = "dsi_hs_mode";
				qcom,mdss-dsi-hbm-on-command-state = "dsi_hs_mode";
				qcom,mdss-dsi-hbm-off-command-state = "dsi_hs_mode";
				qcom,mdss-dsi-lp1-command-state = "dsi_hs_mode";
				qcom,mdss-dsi-nolp-command-state = "dsi_hs_mode";
				qcom,mdss-dsi-aod-high-mode-command-state = "dsi_hs_mode";
				qcom,mdss-dsi-aod-low-mode-command-state = "dsi_hs_mode";
				qcom,mdss-dsi-ultra-low-power-aod-on-command-state = "dsi_hs_mode";
				qcom,mdss-dsi-ultra-low-power-aod-off-command-state = "dsi_hs_mode";
				qcom,mdss-dsi-loading-effect-1-command-state = "dsi_hs_mode";
				qcom,mdss-dsi-loading-effect-2-command-state = "dsi_hs_mode";
				qcom,mdss-dsi-loading-effect-off-command-state = "dsi_hs_mode";
				qcom,panel-roi-alignment=<1440 24 1440 24 1440 24>;
				qcom,partial-update-enabled = "single_roi";

				qcom,lm-split = <720 720>;
				qcom,compression-mode = "dsc";
				qcom,mdss-dsc-encoders = <2>;
				qcom,mdss-dsc-slice-height = <24>;
				qcom,mdss-dsc-slice-width = <720>;
				qcom,mdss-dsc-slice-per-pkt = <2>;
				qcom,mdss-dsc-bit-per-component = <10>;
				qcom,mdss-dsc-bit-per-pixel = <8>;
				qcom,mdss-dsc-version = <0x12>;
				//qcom,mdss-dsc-scr-version = <1>;
				qcom,mdss-dsc-block-prediction-enable;
			};

			timing@wqhd_sdc_120 {
				#include "dsi-panel-samsung-amb670yf07-1440-3216-dsc-cmd-common.dtsi"
				cell-index = <6>;
				qcom,mdss-mdp-transfer-time-us = <7500>;
				qcom,mdss-dsi-panel-framerate = <120>;
				qcom,mdss-dsi-panel-clockrate = <1372000000>;
				qcom,mdss-dsi-panel-width = <1440>;
				qcom,mdss-dsi-panel-height = <3216>;
				qcom,mdss-dsi-h-front-porch = <88>;
				qcom,mdss-dsi-h-back-porch = <57>;
				qcom,mdss-dsi-h-pulse-width = <8>;
				qcom,mdss-dsi-h-sync-pulse = <0>;
				qcom,mdss-dsi-v-back-porch = <8>;
				qcom,mdss-dsi-v-front-porch = <8>;
				qcom,mdss-dsi-v-pulse-width = <8>;

				/* SDC ADFR */
				qcom,mdss-dsi-h-sync-skew = <0>;
				qcom,mdss-dsi-panel-vsync-source = <1>;
				oplus,adfr-fakeframe-config = <3>;
				oplus,adfr-fakeframe-deferred-time = <6>;		/* period*0.7 */
				qcom,mdss-dsi-qsync-min-fps-0 = <1314>;
				qcom,mdss-dsi-qsync-min-fps-1 = <1314>;
				qcom,mdss-dsi-fakeframe-command = [
					05 00 00 40 00 00 01 2C
					05 00 00 40 00 00 01 3C
					05 00 00 40 00 00 01 2C
					05 00 00 40 00 00 01 3C
					05 00 00 00 00 00 01 00
				];

				qcom,mdss-dsi-timing-switch-command = [
					/* CASET/PASET Setting */
					39 00 00 40 00 00 05 2A 00 00 05 9F
					39 00 00 40 00 00 05 2B 00 00 0C 8F
					/* Scaler Setting */
					39 00 00 40 00 00 03 F0 5A 5A
					15 00 00 40 00 00 02 C3 00
					39 00 00 40 00 00 03 F0 A5 A5

					/* OPLUS ADFR OFF */
					39 00 00 40 00 00 03 F0 5A 5A
					39 00 00 40 00 00 03 FC 5A 5A
					15 00 00 40 00 00 02 B9 00						/* TP shift fixed */
					39 00 00 40 00 00 04 B0 00 02 60
					15 00 00 40 00 00 02 60 00						/* OPLUS ADFR OFF */
					39 00 00 40 00 00 03 F2 00 01					/* 0x01,0x00:ADFR ON setting 0x00,0x01:ADFR OFF Setting */
					15 00 00 40 00 00 02 F7 0F
					39 00 00 40 00 00 03 FC A5 A5
					39 00 00 40 00 00 03 F0 A5 A5

					/* TSP_SYNC1 Fixed Setting */
					39 00 00 40 00 00 03 F0 5A 5A
					39 00 00 40 00 00 04 B0 00 22 B9
					39 00 00 40 00 00 03 B9 A1 B1
					39 00 00 40 00 00 04 B0 00 3A B9
					15 00 00 40 00 00 02 B9 02						/* TSP_VSYNC Fixed TE 02:120 03:90 05:60 */
					39 00 00 40 00 00 04 B0 00 26 B9
					39 00 00 40 00 00 03 B9 00 00
					15 00 00 40 00 00 02 F7 0F
					39 00 00 40 00 00 03 F0 A5 A5
					/* TSP_SYNC3 Fixed Setting */
					39 00 00 40 00 00 03 F0 5A 5A
					39 00 00 40 00 00 04 B0 00 24 B9
					15 00 00 40 00 00 02 B9 21
					39 00 00 40 00 00 04 B0 00 38 B9
					15 00 00 40 00 00 02 B9 02						/* TSP_VSYNC Fixed TE 02:120 03:90 05:60 */
					39 00 00 40 00 00 04 B0 00 2A B9
					39 00 00 40 00 00 03 B9 00 00
					15 00 00 40 00 00 02 F7 0F
					39 00 00 40 00 00 03 F0 A5 A5

					/* 120hz Transition */
					39 00 00 40 00 00 03 F0 5A 5A
					39 00 00 40 00 00 04 B0 00 16 F2
					39 00 00 40 00 00 03 F2 1B 50
					39 00 00 40 00 00 04 B0 00 08 CB				/* power saving */
					15 00 00 40 00 00 02 CB 24
					15 00 00 40 00 00 02 60 00
					39 00 00 40 00 00 03 BD 23 02
					39 00 00 40 00 00 04 B0 00 10 BD
					15 00 00 40 00 00 02 BD 00
					39 00 00 40 00 00 04 B0 00 16 BD
					15 00 00 40 00 00 02 BD 77
					39 00 00 40 00 00 04 B0 00 14 BD
					15 00 00 40 00 00 02 BD 00
					15 00 00 40 00 00 02 F7 0F
					39 00 00 00 00 00 03 F0 A5 A5
				];
				qcom,mdss-dsi-on-command = [
					/* DSC Setting */
					39 00 00 00 00 00 5A 9E 12
					00 00 AB 30 80 0C 90 05 A0
					00 18 02 D0 02 D0 02 00 02
					86 00 20 02 83 00 0A 00 0D
					04 86 03 2E 18 00 10 F0 07
					10 20 00 06 0F 0F 33 0E 1C
					2A 38 46 54 62 69 70 77 79
					7B 7D 7E 02 02 22 00 2A 40
					2A BE 3A FC 3A FA 3A F8 3B
					38 3B 78 3B B6 4B B6 4B F4
					4B F4 6C 34 84 74 00
					15 00 00 00 00 00 02 9D 01

					/* Sleep Out(11h) */
					05 00 00 00 06 00 01 11

					/* TSP_SYNC1 Fixed Setting */
					39 00 00 40 00 00 03 F0 5A 5A
					39 00 00 40 00 00 04 B0 00 22 B9
					39 00 00 40 00 00 03 B9 A1 B1
					39 00 00 40 00 00 04 B0 00 3A B9
					15 00 00 40 00 00 02 B9 02						/* TSP_VSYNC Fixed TE 02:120 03:90 05:60 */
					39 00 00 40 00 00 04 B0 00 26 B9
					39 00 00 40 00 00 03 B9 00 00
					15 00 00 40 00 00 02 F7 0F
					39 00 00 00 00 00 03 F0 A5 A5
					/* TSP_SYNC3 Fixed Setting */
					39 00 00 40 00 00 03 F0 5A 5A
					39 00 00 40 00 00 04 B0 00 24 B9
					15 00 00 40 00 00 02 B9 21
					39 00 00 40 00 00 04 B0 00 38 B9
					15 00 00 40 00 00 02 B9 02						/* TSP_VSYNC Fixed TE 02:120 03:90 05:60 */
					39 00 00 40 00 00 04 B0 00 2A B9
					39 00 00 40 00 00 03 B9 00 00
					15 00 00 40 00 00 02 F7 0F
					39 00 00 00 79 00 03 F0 A5 A5

					/* 120hz Transition */
					39 00 00 40 00 00 03 F0 5A 5A
					39 00 00 40 00 00 04 B0 00 16 F2
					39 00 00 40 00 00 03 F2 1B 50
					39 00 00 40 00 00 04 B0 00 08 CB				/* power saving */
					15 00 00 40 00 00 02 CB 24
					15 00 00 40 00 00 02 60 00
					39 00 00 40 00 00 03 BD 23 02
					39 00 00 40 00 00 04 B0 00 10 BD
					15 00 00 40 00 00 02 BD 00
					39 00 00 40 00 00 04 B0 00 16 BD
					15 00 00 40 00 00 02 BD 77
					39 00 00 40 00 00 04 B0 00 14 BD
					15 00 00 40 00 00 02 BD 00
					15 00 00 40 00 00 02 F7 0F
					39 00 00 00 00 00 03 F0 A5 A5

					/* Common Setting */
					39 00 00 40 00 00 03 F0 5A 5A
					39 00 00 40 00 00 03 F2 00 01					/* FQ_CON Setting */
					39 00 00 00 00 00 03 F0 A5 A5
					/* TE(Vsync) ON */
					39 00 00 40 00 00 03 F0 5A 5A
					15 00 00 40 00 00 02 35 00
					15 00 00 40 00 00 02 B9 00
					39 00 00 00 00 00 03 F0 A5 A5
					/* CASET/PASET Setting */
					39 00 00 00 00 00 05 2A 00 00 05 9F
					39 00 00 00 00 00 05 2B 00 00 0C 8F
					/* Scaler Setting */
					39 00 00 40 00 00 03 F0 5A 5A
					15 00 00 40 00 00 02 C3 00
					39 00 00 00 00 00 03 F0 A5 A5
					/* Pre-charge time setting */
					39 00 00 40 00 00 03 F0 5A 5A
					39 00 00 40 00 00 04 B0 00 2B F6
					39 00 00 40 00 00 04 F6 60 63 69
					15 00 00 40 00 00 02 F7 0F
					39 00 00 00 00 00 03 F0 A5 A5
					/* HLPM Power Saving */
					39 00 00 40 00 00 03 F0 5A 5A
					39 00 00 40 00 00 04 B0 00 46 F4
					15 00 00 40 00 00 02 F4 08
					39 00 00 00 00 00 03 F0 A5 A5
					/* DCDC setting of AOD Sequence */
					39 00 00 40 00 00 03 F0 5A 5A
					39 00 00 40 00 00 04 B0 00 18 B1
					39 00 00 40 00 00 02 B1 05
					39 00 00 00 00 00 03 F0 A5 A5

					/* Brightness Control */
					39 00 00 40 00 00 03 F0 5A 5A
					39 00 00 40 00 00 04 B0 00 0D 63
					15 00 00 40 00 00 02 63 01						/* Dimming Setting */
					39 00 00 40 00 00 04 B0 00 0C 63
					15 00 00 40 00 00 02 63 20
					39 00 00 00 00 00 03 F0 A5 A5
					15 00 00 00 00 00 02 53 28
					15 00 00 00 00 00 02 F7 0F
					/* ACL Mode */
					39 00 00 40 00 00 03 F0 5A 5A
					15 00 00 40 00 00 02 55 00
					39 00 00 00 00 00 03 F0 A5 A5
					/* OPEC Setting */
					39 00 00 40 00 00 03 F0 5A 5A
					39 00 00 40 00 00 04 B0 00 52 1F
					15 00 00 40 00 00 02 1F 02
					39 00 00 40 00 00 04 B0 00 54 1F
					15 00 00 40 00 00 02 1F 00
					39 00 00 00 00 00 03 F0 A5 A5
				];

				qcom,mdss-dsi-qsync-on-commands = [
					/* SDC Auto On */
					39 00 00 40 00 00 03 F0 5A 5A
					15 00 00 40 00 00 02 BD 23
					39 00 00 40 00 00 04 B0 00 10 BD
					15 00 00 40 00 00 02 BD 10
					39 00 00 40 00 00 04 B0 00 16 BD
					15 00 00 40 00 00 02 BD 03
					15 00 00 40 00 00 02 F7 0F
					39 00 00 00 00 00 03 F0 A5 A5
				];
				qcom,mdss-dsi-qsync-off-commands = [
					/* SDC Auto Off */
					39 00 00 40 00 00 03 F0 5A 5A
					15 00 00 40 00 00 02 BD 23
					39 00 00 40 00 00 04 B0 00 10 BD
					15 00 00 40 00 00 02 BD 00
					39 00 00 40 00 00 04 B0 00 16 BD
					15 00 00 40 00 00 02 BD 77
					15 00 00 40 00 00 02 F7 0F
					39 00 00 00 00 00 03 F0 A5 A5
				];
				qcom,mdss-dsi-qsync-min-fps-0-command = [
					/* SDC Auto Off */
					39 00 00 40 00 00 03 F0 5A 5A
					39 00 00 40 00 00 04 B0 00 14 BD
					15 00 00 40 00 00 02 BD 00
					15 00 00 40 00 00 02 F7 0F
					39 00 00 00 00 00 03 F0 A5 A5
				];
				qcom,mdss-dsi-qsync-min-fps-1-command = [
					/* SDC Auto On */
					39 00 00 40 00 00 03 F0 5A 5A
					39 00 00 40 00 00 04 B0 00 14 BD
					15 00 00 40 00 00 02 BD 00
					15 00 00 40 00 00 02 F7 0F
					39 00 00 00 00 00 03 F0 A5 A5
				];

				qcom,mdss-dsi-fakeframe-command-state = "dsi_hs_mode";
				qcom,mdss-dsi-qsync-on-commands-state ="dsi_hs_mode";
				qcom,mdss-dsi-qsync-off-commands-state ="dsi_hs_mode";
				qcom,mdss-dsi-qsync-min-fps-0-command-state = "dsi_hs_mode";
				qcom,mdss-dsi-qsync-min-fps-1-command-state = "dsi_hs_mode";
				qcom,panel-roi-alignment=<1440 24 1440 24 1440 24>;
				qcom,partial-update-enabled = "single_roi";

				qcom,lm-split = <720 720>;
				qcom,mdss-dsc-slice-height = <24>;
				qcom,mdss-dsc-slice-width = <720>;
			};

			timing@wqhd_oplus_120 {
				#include "dsi-panel-samsung-amb670yf07-1440-3216-dsc-cmd-common.dtsi"
				cell-index = <7>;
				qcom,mdss-mdp-transfer-time-us = <7500>;
				qcom,mdss-dsi-panel-framerate = <120>;
				qcom,mdss-dsi-panel-clockrate = <1372000000>;
				qcom,mdss-dsi-panel-width = <1440>;
				qcom,mdss-dsi-panel-height = <3216>;
				qcom,mdss-dsi-h-front-porch = <88>;
				qcom,mdss-dsi-h-back-porch = <61>;
				qcom,mdss-dsi-h-pulse-width = <8>;
				qcom,mdss-dsi-h-sync-pulse = <0>;
				qcom,mdss-dsi-v-back-porch = <8>;
				qcom,mdss-dsi-v-front-porch = <8>;
				qcom,mdss-dsi-v-pulse-width = <8>;

				/* OPLUS ADFR */
				qcom,mdss-dsi-h-sync-skew = <2>;
				qcom,mdss-dsi-qsync-min-fps-0 = <6>;
				qcom,mdss-dsi-qsync-min-fps-1 = <8>;
				qcom,mdss-dsi-qsync-min-fps-2 = <10>;
				qcom,mdss-dsi-qsync-min-fps-3 = <12>;
				qcom,mdss-dsi-qsync-min-fps-4 = <15>;
				qcom,mdss-dsi-qsync-min-fps-5 = <20>;
				qcom,mdss-dsi-qsync-min-fps-6 = <24>;
				qcom,mdss-dsi-qsync-min-fps-7 = <30>;
				qcom,mdss-dsi-qsync-min-fps-8 = <40>;
				qcom,mdss-dsi-qsync-min-fps-9 = <60>;

				qcom,mdss-dsi-timing-switch-command = [
					/* CASET/PASET Setting */
					39 00 00 40 00 00 05 2A 00 00 05 9F
					39 00 00 40 00 00 05 2B 00 00 0C 8F
					/* Scaler Setting */
					39 00 00 40 00 00 03 F0 5A 5A
					15 00 00 40 00 00 02 C3 00
					39 00 00 40 00 00 03 F0 A5 A5

					/* OPLUS ADFR OFF */
					39 00 00 40 00 00 03 F0 5A 5A
					39 00 00 40 00 00 03 FC 5A 5A
					15 00 00 40 00 00 02 B9 00						/* TP shift fixed */
					39 00 00 40 00 00 04 B0 00 02 60
					15 00 00 40 00 00 02 60 00						/* OPLUS ADFR OFF */
					39 00 00 40 00 00 03 F2 00 01					/* 0x01,0x00:ADFR ON setting 0x00,0x01:ADFR OFF Setting */
					15 00 00 40 00 00 02 F7 0F
					39 00 00 40 00 00 03 FC A5 A5
					39 00 00 40 00 00 03 F0 A5 A5

					/* TSP_SYNC1 Fixed Setting */
					39 00 00 40 00 00 03 F0 5A 5A
					39 00 00 40 00 00 04 B0 00 22 B9
					39 00 00 40 00 00 03 B9 A1 B1
					39 00 00 40 00 00 04 B0 00 3A B9
					15 00 00 40 00 00 02 B9 02						/* TSP_VSYNC Fixed TE 02:120 03:90 05:60 */
					39 00 00 40 00 00 04 B0 00 26 B9
					39 00 00 40 00 00 03 B9 00 00
					15 00 00 40 00 00 02 F7 0F
					39 00 00 40 00 00 03 F0 A5 A5
					/* TSP_SYNC3 Fixed Setting */
					39 00 00 40 00 00 03 F0 5A 5A
					39 00 00 40 00 00 04 B0 00 24 B9
					15 00 00 40 00 00 02 B9 21
					39 00 00 40 00 00 04 B0 00 38 B9
					15 00 00 40 00 00 02 B9 02						/* TSP_VSYNC Fixed TE 02:120 03:90 05:60 */
					39 00 00 40 00 00 04 B0 00 2A B9
					39 00 00 40 00 00 03 B9 00 00
					15 00 00 40 00 00 02 F7 0F
					39 00 00 40 00 00 03 F0 A5 A5

					/* 120hz Transition */
					39 00 00 40 00 00 03 F0 5A 5A
					39 00 00 40 00 00 04 B0 00 16 F2
					39 00 00 40 00 00 03 F2 1B 50
					39 00 00 40 00 00 04 B0 00 08 CB				/* power saving */
					15 00 00 40 00 00 02 CB 24
					15 00 00 40 00 00 02 60 00
					39 00 00 40 00 00 03 BD 23 02
					39 00 00 40 00 00 04 B0 00 10 BD
					15 00 00 40 00 00 02 BD 00
					39 00 00 40 00 00 04 B0 00 16 BD
					15 00 00 40 00 00 02 BD 77
					39 00 00 40 00 00 04 B0 00 14 BD
					15 00 00 40 00 00 02 BD 00
					15 00 00 40 00 00 02 F7 0F
					39 00 00 00 00 00 03 F0 A5 A5
				];
				qcom,mdss-dsi-on-command = [
					/* DSC Setting */
					39 00 00 00 00 00 5A 9E 12
					00 00 AB 30 80 0C 90 05 A0
					00 43 02 D0 02 D0 02 00 02
					C2 00 20 06 89 00 0A 00 0F
					01 D2 01 24 18 00 10 F0 07
					10 20 00 06 0F 0F 33 0E 1C
					2A 38 46 54 62 69 70 77 79
					7B 7D 7E 02 02 22 00 2A 40
					2A BE 3A FC 3A FA 3A F8 3B
					38 3B 78 3B B6 4B B6 4B F4
					4B F4 6C 34 84 74 00
					15 00 00 00 00 00 02 9D 01

					/* Sleep Out(11h) */
					05 00 00 00 06 00 01 11

					/* TSP_SYNC1 Fixed Setting */
					39 00 00 40 00 00 03 F0 5A 5A
					39 00 00 40 00 00 04 B0 00 22 B9
					39 00 00 40 00 00 03 B9 A1 B1
					39 00 00 40 00 00 04 B0 00 3A B9
					15 00 00 40 00 00 02 B9 02						/* TSP_VSYNC Fixed TE 02:120 03:90 05:60 */
					39 00 00 40 00 00 04 B0 00 26 B9
					39 00 00 40 00 00 03 B9 00 00
					15 00 00 40 00 00 02 F7 0F
					39 00 00 00 00 00 03 F0 A5 A5
					/* TSP_SYNC3 Fixed Setting */
					39 00 00 40 00 00 03 F0 5A 5A
					39 00 00 40 00 00 04 B0 00 24 B9
					15 00 00 40 00 00 02 B9 21
					39 00 00 40 00 00 04 B0 00 38 B9
					15 00 00 40 00 00 02 B9 02						/* TSP_VSYNC Fixed TE 02:120 03:90 05:60 */
					39 00 00 40 00 00 04 B0 00 2A B9
					39 00 00 40 00 00 03 B9 00 00
					15 00 00 40 00 00 02 F7 0F
					39 00 00 00 79 00 03 F0 A5 A5

					/* 120hz Transition */
					39 00 00 40 00 00 03 F0 5A 5A
					39 00 00 40 00 00 04 B0 00 16 F2
					39 00 00 40 00 00 03 F2 1B 50
					39 00 00 40 00 00 04 B0 00 08 CB				/* power saving */
					15 00 00 40 00 00 02 CB 24
					15 00 00 40 00 00 02 60 00
					39 00 00 40 00 00 03 BD 23 02
					39 00 00 40 00 00 04 B0 00 10 BD
					15 00 00 40 00 00 02 BD 00
					39 00 00 40 00 00 04 B0 00 16 BD
					15 00 00 40 00 00 02 BD 77
					39 00 00 40 00 00 04 B0 00 14 BD
					15 00 00 40 00 00 02 BD 00
					15 00 00 40 00 00 02 F7 0F
					39 00 00 00 00 00 03 F0 A5 A5

					/* Common Setting */
					39 00 00 40 00 00 03 F0 5A 5A
					39 00 00 40 00 00 03 F2 00 01					/* FQ_CON Setting */
					39 00 00 00 00 00 03 F0 A5 A5
					/* TE(Vsync) ON */
					39 00 00 40 00 00 03 F0 5A 5A
					15 00 00 40 00 00 02 35 00
					15 00 00 40 00 00 02 B9 00
					39 00 00 00 00 00 03 F0 A5 A5
					/* CASET/PASET Setting */
					39 00 00 00 00 00 05 2A 00 00 05 9F
					39 00 00 00 00 00 05 2B 00 00 0C 8F
					/* Scaler Setting */
					39 00 00 40 00 00 03 F0 5A 5A
					15 00 00 40 00 00 02 C3 00
					39 00 00 00 00 00 03 F0 A5 A5
					/* Pre-charge time setting */
					39 00 00 40 00 00 03 F0 5A 5A
					39 00 00 40 00 00 04 B0 00 2B F6
					39 00 00 40 00 00 04 F6 60 63 69
					15 00 00 40 00 00 02 F7 0F
					39 00 00 00 00 00 03 F0 A5 A5
					/* HLPM Power Saving */
					39 00 00 40 00 00 03 F0 5A 5A
					39 00 00 40 00 00 04 B0 00 46 F4
					15 00 00 40 00 00 02 F4 08
					39 00 00 00 00 00 03 F0 A5 A5
					/* DCDC setting of AOD Sequence */
					39 00 00 40 00 00 03 F0 5A 5A
					39 00 00 40 00 00 04 B0 00 18 B1
					39 00 00 40 00 00 02 B1 05
					39 00 00 00 00 00 03 F0 A5 A5

					/* Brightness Control */
					39 00 00 40 00 00 03 F0 5A 5A
					39 00 00 40 00 00 04 B0 00 0D 63
					15 00 00 40 00 00 02 63 01						/* Dimming Setting */
					39 00 00 40 00 00 04 B0 00 0C 63
					15 00 00 40 00 00 02 63 20
					39 00 00 00 00 00 03 F0 A5 A5
					15 00 00 00 00 00 02 53 28
					15 00 00 00 00 00 02 F7 0F
					/* ACL Mode */
					39 00 00 40 00 00 03 F0 5A 5A
					15 00 00 40 00 00 02 55 00
					39 00 00 00 00 00 03 F0 A5 A5
					/* OPEC Setting */
					39 00 00 40 00 00 03 F0 5A 5A
					39 00 00 40 00 00 04 B0 00 52 1F
					15 00 00 40 00 00 02 1F 02
					39 00 00 40 00 00 04 B0 00 54 1F
					15 00 00 40 00 00 02 1F 00
					39 00 00 00 00 00 03 F0 A5 A5
				];

				qcom,mdss-dsi-qsync-on-commands = [
				];
				qcom,mdss-dsi-qsync-off-commands = [
					39 00 00 40 00 00 03 F0 5A 5A
					39 00 00 40 00 00 04 B0 00 14 BD
					15 00 00 40 00 00 02 BD 00
					15 00 00 40 00 00 02 F7 0F
					39 00 00 00 00 00 03 F0 A5 A5
				];
				qcom,mdss-dsi-qsync-min-fps-0-command = [
					39 00 00 40 00 00 03 F0 5A 5A
					39 00 00 40 00 00 04 B0 00 14 BD
					15 00 00 40 00 00 02 BD 13
					15 00 00 40 00 00 02 F7 0F
					39 00 00 00 00 00 03 F0 A5 A5
				];
				qcom,mdss-dsi-qsync-min-fps-1-command = [
					39 00 00 40 00 00 03 F0 5A 5A
					39 00 00 40 00 00 04 B0 00 14 BD
					15 00 00 40 00 00 02 BD 0E
					15 00 00 40 00 00 02 F7 0F
					39 00 00 00 00 00 03 F0 A5 A5
				];
				qcom,mdss-dsi-qsync-min-fps-2-command = [
					39 00 00 40 00 00 03 F0 5A 5A
					39 00 00 40 00 00 04 B0 00 14 BD
					15 00 00 40 00 00 02 BD 0B
					15 00 00 40 00 00 02 F7 0F
					39 00 00 00 00 00 03 F0 A5 A5
				];
				qcom,mdss-dsi-qsync-min-fps-3-command = [
					39 00 00 40 00 00 03 F0 5A 5A
					39 00 00 40 00 00 04 B0 00 14 BD
					15 00 00 40 00 00 02 BD 09
					15 00 00 40 00 00 02 F7 0F
					39 00 00 00 00 00 03 F0 A5 A5
				];
				qcom,mdss-dsi-qsync-min-fps-4-command = [
					39 00 00 40 00 00 03 F0 5A 5A
					39 00 00 40 00 00 04 B0 00 14 BD
					15 00 00 40 00 00 02 BD 07
					15 00 00 40 00 00 02 F7 0F
					39 00 00 00 00 00 03 F0 A5 A5
				];
				qcom,mdss-dsi-qsync-min-fps-5-command = [
					39 00 00 40 00 00 03 F0 5A 5A
					39 00 00 40 00 00 04 B0 00 14 BD
					15 00 00 40 00 00 02 BD 05
					15 00 00 40 00 00 02 F7 0F
					39 00 00 00 00 00 03 F0 A5 A5
				];
				qcom,mdss-dsi-qsync-min-fps-6-command = [
					39 00 00 40 00 00 03 F0 5A 5A
					39 00 00 40 00 00 04 B0 00 14 BD
					15 00 00 40 00 00 02 BD 04
					15 00 00 40 00 00 02 F7 0F
					39 00 00 00 00 00 03 F0 A5 A5
				];
				qcom,mdss-dsi-qsync-min-fps-7-command = [
					39 00 00 40 00 00 03 F0 5A 5A
					39 00 00 40 00 00 04 B0 00 14 BD
					15 00 00 40 00 00 02 BD 03
					15 00 00 40 00 00 02 F7 0F
					39 00 00 00 00 00 03 F0 A5 A5
				];
				qcom,mdss-dsi-qsync-min-fps-8-command = [
					39 00 00 40 00 00 03 F0 5A 5A
					39 00 00 40 00 00 04 B0 00 14 BD
					15 00 00 40 00 00 02 BD 02
					15 00 00 40 00 00 02 F7 0F
					39 00 00 00 00 00 03 F0 A5 A5
				];
				qcom,mdss-dsi-qsync-min-fps-9-command = [
					39 00 00 40 00 00 03 F0 5A 5A
					39 00 00 40 00 00 04 B0 00 14 BD
					15 00 00 40 00 00 02 BD 01
					15 00 00 40 00 00 02 F7 0F
					39 00 00 00 00 00 03 F0 A5 A5
				];

				qcom,mdss-dsi-qsync-on-commands-state ="dsi_hs_mode";
				qcom,mdss-dsi-qsync-off-commands-state ="dsi_hs_mode";
				qcom,mdss-dsi-qsync-min-fps-0-command-state = "dsi_hs_mode";
				qcom,mdss-dsi-qsync-min-fps-1-command-state = "dsi_hs_mode";
				qcom,mdss-dsi-qsync-min-fps-2-command-state = "dsi_hs_mode";
				qcom,mdss-dsi-qsync-min-fps-3-command-state = "dsi_hs_mode";
				qcom,mdss-dsi-qsync-min-fps-4-command-state = "dsi_hs_mode";
				qcom,mdss-dsi-qsync-min-fps-5-command-state = "dsi_hs_mode";
				qcom,mdss-dsi-qsync-min-fps-6-command-state = "dsi_hs_mode";
				qcom,mdss-dsi-qsync-min-fps-7-command-state = "dsi_hs_mode";
				qcom,mdss-dsi-qsync-min-fps-8-command-state = "dsi_hs_mode";
				qcom,mdss-dsi-qsync-min-fps-9-command-state = "dsi_hs_mode";
				qcom,panel-roi-alignment=<1440 24 1440 24 1440 24>;
				qcom,partial-update-enabled = "single_roi";

				qcom,lm-split = <720 720>;
				qcom,mdss-dsc-slice-height = <24>;
				qcom,mdss-dsc-slice-width = <720>;
			};
		};
	};
};

&dsi_panel_samsung_amb670yf07_1440_3216_dsc_cmd {
	/* hardware config */
	qcom,panel-supply-entries = <&dsi_panel_oplus_optimization_pwr_supply>;
	qcom,mdss-dsi-panel-controller = <&mdss_dsi0>;
	qcom,platform-te-gpio = <&tlmm 86 0>;
	qcom,platform-te-gpio-1 = <&tlmm 87 0>;
	qcom,dynamic-te-gpio = <&tlmm 88 0>;
	qcom,platform-reset-gpio = <&tlmm 3 0>;
	qcom,platform-panel-vout-gpio = <&tlmm 90 0>;
	//qcom,platform-panel-vddr-aod-en-gpio = <&tlmm 180 0>;
	qcom,panel_voltage_vddi_name = "vddio";
	qcom,panel_voltage_vddi = <0 1800000 1850000 1950000>;
	qcom,panel_voltage_vddr_name = "vddio";
	qcom,panel_voltage_vddr = <1 1800000 1850000 1950000>;
	//oplus,esd-check-flag-enabled;

	/* brightness config */
	qcom,mdss-dsi-bl-pmic-control-type = "bl_ctrl_dcs";
	qcom,bl-dsc-cmd-state = "dsi_lp_mode";
	qcom,mdss-dsi-bl-inverted-dbv;
	qcom,mdss-dsi-bl-min-level = <1>;
	qcom,mdss-dsi-bl-max-level = <4095>;
	qcom,mdss-brightness-max-level = <4095>;
	oplus,dsi-bl-normal-max-level = <2047>;
	oplus,dsi-brightness-normal-max-level = <2047>;
	oplus,dsi-brightness-default-level = <400>;
	oplus,dsi-global-hbm-case-id = <4>;

	/* ofp config */
	oplus,ofp-fp-type = <0x88>;
	oplus,ofp-need-to-wait-data-before-aod-on;

	/* factory config */
	oplus,mdss-dsi-vendor-name = "S6E3HC3";
	oplus,mdss-dsi-manufacture = "samsung1024";
	oplus,color_vivid_status;
	oplus,color_srgb_status;
	oplus,apollo_backlight_enable;
	oplus,color_softiris_status;
	oplus,color_dual_brightness_status;

	/* oplus features config */
	oplus,dp-enabled;
	//oplus,dsi-cabc-enabled;
	//oplus,dsi-dre-enabled;
	oplus,dsi-serial-number-enabled;
	//oplus,dsi-serial-number-lock;
	oplus,dsi-serial-number-reg= <0xA1>;
	oplus,dsi-serial-number-index= <4>;
	oplus,dsi-serial-number-read-count= <11>;

	/* adfr config */
	/* just for qsync enable*/
	qcom,qsync-enable;
	qcom,mdss-dsi-qsync-min-refresh-rate = <24>;
	/*
	** 0st bit: adfr global on/off
	** 1st bit: fakeframe on/off
	** 2st bit: switch on/off
	** 3rd bit: 0:double-TE switch 1:external TE/TP switch
	** 4rd bit: idle mode on/off
	*/
	oplus,adfr-config = <23>;
};

&soc {
	dsi_panel_samsung_amb670yf07_1440_3216_dsc_cmd {
		qcom,dsi-display-active;
	};
};

&dsi_panel_samsung_amb670yf07_1440_3216_dsc_cmd {
	qcom,ulps-enabled;
	qcom,dsi-select-clocks = "pll_byte_clk0", "pll_dsi_clk0";
	qcom,mdss-dsi-display-timings {
		timing@fhd_sdc_120 {
			qcom,mdss-dsi-panel-phy-timings = [00 1C 07 07 17 22 07 07 08 02 04 00 18 0C];
			qcom,display-topology = <1 1 1>,<2 2 1>;
			qcom,default-topology-index = <1>;
		};
		timing@fhd_sdc_90 {
			qcom,mdss-dsi-panel-phy-timings = [00 1C 07 07 17 22 07 07 08 02 04 00 18 0C];
			qcom,display-topology = <1 1 1>,<2 2 1>;
			qcom,default-topology-index = <1>;
		};
		timing@fhd_sdc_60 {
			qcom,mdss-dsi-panel-phy-timings = [00 1C 07 07 17 22 07 07 08 02 04 00 18 0C];
			qcom,display-topology = <1 1 1>,<2 2 1>;
			qcom,default-topology-index = <1>;
		};
		timing@fhd_oplus_120 {
			qcom,mdss-dsi-panel-phy-timings = [00 1C 07 07 17 22 07 07 08 02 04 00 18 0C];
			qcom,display-topology = <1 1 1>,<2 2 1>;
			qcom,default-topology-index = <1>;
		};
		timing@wqhd_sdc_60 {
			qcom,mdss-dsi-panel-phy-timings = [00 2C 0C 0C 1D 22 09 0C 0B 02 04 00 24 11];
			qcom,display-topology = <1 1 1>,<2 2 1>;
			qcom,default-topology-index = <1>;
		};
		timing@wqhd_sdc_90 {
			qcom,mdss-dsi-panel-phy-timings = [00 2C 0C 0C 1D 22 09 0C 0B 02 04 00 24 11];
			qcom,display-topology = <1 1 1>,<2 2 1>;
			qcom,default-topology-index = <1>;
		};
		timing@wqhd_sdc_120 {
			qcom,mdss-dsi-panel-phy-timings = [00 2C 0C 0C 1D 22 09 0C 0B 02 04 00 24 11];
			qcom,display-topology = <1 1 1>,<2 2 1>;
			qcom,default-topology-index = <1>;
		};
		timing@wqhd_oplus_120 {
			qcom,mdss-dsi-panel-phy-timings = [00 2C 0C 0C 1D 22 09 0C 0B 02 04 00 24 11];
			qcom,display-topology = <1 1 1>,<2 2 1>;
			qcom,default-topology-index = <1>;
		};
	};
};

